[part 4 of 6: packages /MICROSAR/KeyM_swc/Interfaces to /MICROSAR/KeyM_swc/ComponentTypes]
AUTOSAR XML (schema 00049)
package /MICROSAR/KeyM_swc/Interfaces  (continued)
  153 x client server interface, all with is-service=true, service-kind=VENDOR-SPECIFIC:  (continued)
    KeyMCertificateElement_Ssa_TrustModelEcuCsr_SigAlgoId_008  # Service of the certificate sub module to access certificate elements.
      operation CertificateElementGet: possible-error=[KeyMCertificateElement_Ssa_TrustModelEcuCsr_SigAlgoId_008/E_NOT_OK, KeyMCertificateElement_Ssa_TrustModelEcuCsr_SigAlgoId_008/KEYM_E_KEY_CERT_SIZE_MISMATCH, KeyMCertificateElement_Ssa_TrustModelEcuCsr_SigAlgoId_008/KEYM_E_PARAMETER_MISMATCH, KeyMCertificateElement_Ssa_TrustModelEcuCsr_SigAlgoId_008/KEYM_E_KEY_CERT_INVALID, KeyMCertificateElement_Ssa_TrustModelEcuCsr_SigAlgoId_008/KEYM_E_KEY_CERT_EMPTY]  # Provides the content of a specific certificate element. The certificate configuration defines how the certificate submodule can find the element, e.g. by providing the object identifier (OID). This function is used to retrieve this information if only one element is assigned to the respective OID.
        arg CertificateElementData: type=KeyM_CertificateElementType_Ssa_TrustModelEcuCsr_SigAlgoId_008, direction=OUT, server-argument-impl-policy=USE-ARRAY-BASE-TYPE  # Holds a pointer to the memory location which will hold the certificate element.
        arg CertificateDataLength: type=uint32, direction=OUT  # Contains the length in bytes of certificate element.
      operation CertificateElementGetByIndex: possible-error=[KeyMCertificateElement_Ssa_TrustModelEcuCsr_SigAlgoId_008/E_NOT_OK, KeyMCertificateElement_Ssa_TrustModelEcuCsr_SigAlgoId_008/KEYM_E_KEY_CERT_SIZE_MISMATCH, KeyMCertificateElement_Ssa_TrustModelEcuCsr_SigAlgoId_008/KEYM_E_PARAMETER_MISMATCH, KeyMCertificateElement_Ssa_TrustModelEcuCsr_SigAlgoId_008/KEYM_E_KEY_CERT_INVALID, KeyMCertificateElement_Ssa_TrustModelEcuCsr_SigAlgoId_008/KEYM_E_KEY_CERT_EMPTY]  # This operation provides data from a specific certificate element.
        arg Index: type=uint16, direction=IN  # This is the index to dedicated element in the list
        arg CertificateElementData: type=KeyM_CertificateElementType_Ssa_TrustModelEcuCsr_SigAlgoId_008, direction=OUT, server-argument-impl-policy=USE-ARRAY-BASE-TYPE  # Holds a pointer to the memory location which will hold the certificate element.
        arg CertificateDataLength: type=uint32, direction=OUT  # Contains the length in bytes of certificate element.
      operation CertificateElementGetCount: possible-error=[KeyMCertificateElement_Ssa_TrustModelEcuCsr_SigAlgoId_008/E_NOT_OK, KeyMCertificateElement_Ssa_TrustModelEcuCsr_SigAlgoId_008/KEYM_E_KEY_CERT_SIZE_MISMATCH, KeyMCertificateElement_Ssa_TrustModelEcuCsr_SigAlgoId_008/KEYM_E_PARAMETER_MISMATCH, KeyMCertificateElement_Ssa_TrustModelEcuCsr_SigAlgoId_008/KEYM_E_KEY_CERT_INVALID, KeyMCertificateElement_Ssa_TrustModelEcuCsr_SigAlgoId_008/KEYM_E_KEY_CERT_EMPTY]  # This operation returns the amount of items available for a certificate element.
        arg count: type=uint16, direction=OUT  # Number of items available for an element.
      5 x error:
        E_NOT_OK: error-code=1  # The service request failed.
        KEYM_E_KEY_CERT_SIZE_MISMATCH: error-code=4  # The service request failed. Parameter size does not match the expected value.
        KEYM_E_PARAMETER_MISMATCH: error-code=5  # The service request failed. Parameter to function does not provide the expected value.
        KEYM_E_KEY_CERT_EMPTY: error-code=10  # The service request failed. The requested key or certificate is not available, slot is empty.
        KEYM_E_KEY_CERT_INVALID: error-code=6  # The service request failed. Key or certificate is invalid and cannot be used for the operation.
    KeyMCertificateElement_Ssa_TrustModelEcuCsr_validityNotBefore_008  # Service of the certificate sub module to access certificate elements.
      operation CertificateElementGet: possible-error=[KeyMCertificateElement_Ssa_TrustModelEcuCsr_validityNotBefore_008/E_NOT_OK, KeyMCertificateElement_Ssa_TrustModelEcuCsr_validityNotBefore_008/KEYM_E_KEY_CERT_SIZE_MISMATCH, KeyMCertificateElement_Ssa_TrustModelEcuCsr_validityNotBefore_008/KEYM_E_PARAMETER_MISMATCH, KeyMCertificateElement_Ssa_TrustModelEcuCsr_validityNotBefore_008/KEYM_E_KEY_CERT_INVALID, KeyMCertificateElement_Ssa_TrustModelEcuCsr_validityNotBefore_008/KEYM_E_KEY_CERT_EMPTY]  # Provides the content of a specific certificate element. The certificate configuration defines how the certificate submodule can find the element, e.g. by providing the object identifier (OID). This function is used to retrieve this information if only one element is assigned to the respective OID.
        arg CertificateElementData: type=KeyM_CertificateElementType_Ssa_TrustModelEcuCsr_validityNotBefore_008, direction=OUT, server-argument-impl-policy=USE-ARRAY-BASE-TYPE  # Holds a pointer to the memory location which will hold the certificate element.
        arg CertificateDataLength: type=uint32, direction=OUT  # Contains the length in bytes of certificate element.
      operation CertificateElementGetByIndex: possible-error=[KeyMCertificateElement_Ssa_TrustModelEcuCsr_validityNotBefore_008/E_NOT_OK, KeyMCertificateElement_Ssa_TrustModelEcuCsr_validityNotBefore_008/KEYM_E_KEY_CERT_SIZE_MISMATCH, KeyMCertificateElement_Ssa_TrustModelEcuCsr_validityNotBefore_008/KEYM_E_PARAMETER_MISMATCH, KeyMCertificateElement_Ssa_TrustModelEcuCsr_validityNotBefore_008/KEYM_E_KEY_CERT_INVALID, KeyMCertificateElement_Ssa_TrustModelEcuCsr_validityNotBefore_008/KEYM_E_KEY_CERT_EMPTY]  # This operation provides data from a specific certificate element.
        arg Index: type=uint16, direction=IN  # This is the index to dedicated element in the list
        arg CertificateElementData: type=KeyM_CertificateElementType_Ssa_TrustModelEcuCsr_validityNotBefore_008, direction=OUT, server-argument-impl-policy=USE-ARRAY-BASE-TYPE  # Holds a pointer to the memory location which will hold the certificate element.
        arg CertificateDataLength: type=uint32, direction=OUT  # Contains the length in bytes of certificate element.
      operation CertificateElementGetCount: possible-error=[KeyMCertificateElement_Ssa_TrustModelEcuCsr_validityNotBefore_008/E_NOT_OK, KeyMCertificateElement_Ssa_TrustModelEcuCsr_validityNotBefore_008/KEYM_E_KEY_CERT_SIZE_MISMATCH, KeyMCertificateElement_Ssa_TrustModelEcuCsr_validityNotBefore_008/KEYM_E_PARAMETER_MISMATCH, KeyMCertificateElement_Ssa_TrustModelEcuCsr_validityNotBefore_008/KEYM_E_KEY_CERT_INVALID, KeyMCertificateElement_Ssa_TrustModelEcuCsr_validityNotBefore_008/KEYM_E_KEY_CERT_EMPTY]  # This operation returns the amount of items available for a certificate element.
        arg count: type=uint16, direction=OUT  # Number of items available for an element.
      5 x error:
        E_NOT_OK: error-code=1  # The service request failed.
        KEYM_E_KEY_CERT_SIZE_MISMATCH: error-code=4  # The service request failed. Parameter size does not match the expected value.
        KEYM_E_PARAMETER_MISMATCH: error-code=5  # The service request failed. Parameter to function does not provide the expected value.
        KEYM_E_KEY_CERT_EMPTY: error-code=10  # The service request failed. The requested key or certificate is not available, slot is empty.
        KEYM_E_KEY_CERT_INVALID: error-code=6  # The service request failed. Key or certificate is invalid and cannot be used for the operation.
    KeyMCertificateElement_Ssa_TrustModelEcuCsr_validityNotAfter_008  # Service of the certificate sub module to access certificate elements.
      operation CertificateElementGet: possible-error=[KeyMCertificateElement_Ssa_TrustModelEcuCsr_validityNotAfter_008/E_NOT_OK, KeyMCertificateElement_Ssa_TrustModelEcuCsr_validityNotAfter_008/KEYM_E_KEY_CERT_SIZE_MISMATCH, KeyMCertificateElement_Ssa_TrustModelEcuCsr_validityNotAfter_008/KEYM_E_PARAMETER_MISMATCH, KeyMCertificateElement_Ssa_TrustModelEcuCsr_validityNotAfter_008/KEYM_E_KEY_CERT_INVALID, KeyMCertificateElement_Ssa_TrustModelEcuCsr_validityNotAfter_008/KEYM_E_KEY_CERT_EMPTY]  # Provides the content of a specific certificate element. The certificate configuration defines how the certificate submodule can find the element, e.g. by providing the object identifier (OID). This function is used to retrieve this information if only one element is assigned to the respective OID.
        arg CertificateElementData: type=KeyM_CertificateElementType_Ssa_TrustModelEcuCsr_validityNotAfter_008, direction=OUT, server-argument-impl-policy=USE-ARRAY-BASE-TYPE  # Holds a pointer to the memory location which will hold the certificate element.
        arg CertificateDataLength: type=uint32, direction=OUT  # Contains the length in bytes of certificate element.
      operation CertificateElementGetByIndex: possible-error=[KeyMCertificateElement_Ssa_TrustModelEcuCsr_validityNotAfter_008/E_NOT_OK, KeyMCertificateElement_Ssa_TrustModelEcuCsr_validityNotAfter_008/KEYM_E_KEY_CERT_SIZE_MISMATCH, KeyMCertificateElement_Ssa_TrustModelEcuCsr_validityNotAfter_008/KEYM_E_PARAMETER_MISMATCH, KeyMCertificateElement_Ssa_TrustModelEcuCsr_validityNotAfter_008/KEYM_E_KEY_CERT_INVALID, KeyMCertificateElement_Ssa_TrustModelEcuCsr_validityNotAfter_008/KEYM_E_KEY_CERT_EMPTY]  # This operation provides data from a specific certificate element.
        arg Index: type=uint16, direction=IN  # This is the index to dedicated element in the list
        arg CertificateElementData: type=KeyM_CertificateElementType_Ssa_TrustModelEcuCsr_validityNotAfter_008, direction=OUT, server-argument-impl-policy=USE-ARRAY-BASE-TYPE  # Holds a pointer to the memory location which will hold the certificate element.
        arg CertificateDataLength: type=uint32, direction=OUT  # Contains the length in bytes of certificate element.
      operation CertificateElementGetCount: possible-error=[KeyMCertificateElement_Ssa_TrustModelEcuCsr_validityNotAfter_008/E_NOT_OK, KeyMCertificateElement_Ssa_TrustModelEcuCsr_validityNotAfter_008/KEYM_E_KEY_CERT_SIZE_MISMATCH, KeyMCertificateElement_Ssa_TrustModelEcuCsr_validityNotAfter_008/KEYM_E_PARAMETER_MISMATCH, KeyMCertificateElement_Ssa_TrustModelEcuCsr_validityNotAfter_008/KEYM_E_KEY_CERT_INVALID, KeyMCertificateElement_Ssa_TrustModelEcuCsr_validityNotAfter_008/KEYM_E_KEY_CERT_EMPTY]  # This operation returns the amount of items available for a certificate element.
        arg count: type=uint16, direction=OUT  # Number of items available for an element.
      5 x error:
        E_NOT_OK: error-code=1  # The service request failed.
        KEYM_E_KEY_CERT_SIZE_MISMATCH: error-code=4  # The service request failed. Parameter size does not match the expected value.
        KEYM_E_PARAMETER_MISMATCH: error-code=5  # The service request failed. Parameter to function does not provide the expected value.
        KEYM_E_KEY_CERT_EMPTY: error-code=10  # The service request failed. The requested key or certificate is not available, slot is empty.
        KEYM_E_KEY_CERT_INVALID: error-code=6  # The service request failed. Key or certificate is invalid and cannot be used for the operation.
    KeyMCertificateElement_Ssa_TrustModelEcuCsr_subject_008  # Service of the certificate sub module to access certificate elements.
      operation CertificateElementGet: possible-error=[KeyMCertificateElement_Ssa_TrustModelEcuCsr_subject_008/E_NOT_OK, KeyMCertificateElement_Ssa_TrustModelEcuCsr_subject_008/KEYM_E_KEY_CERT_SIZE_MISMATCH, KeyMCertificateElement_Ssa_TrustModelEcuCsr_subject_008/KEYM_E_PARAMETER_MISMATCH, KeyMCertificateElement_Ssa_TrustModelEcuCsr_subject_008/KEYM_E_KEY_CERT_INVALID, KeyMCertificateElement_Ssa_TrustModelEcuCsr_subject_008/KEYM_E_KEY_CERT_EMPTY]  # Provides the content of a specific certificate element. The certificate configuration defines how the certificate submodule can find the element, e.g. by providing the object identifier (OID). This function is used to retrieve this information if only one element is assigned to the respective OID.
        arg CertificateElementData: type=KeyM_CertificateElementType_Ssa_TrustModelEcuCsr_subject_008, direction=OUT, server-argument-impl-policy=USE-ARRAY-BASE-TYPE  # Holds a pointer to the memory location which will hold the certificate element.
        arg CertificateDataLength: type=uint32, direction=OUT  # Contains the length in bytes of certificate element.
      operation CertificateElementGetByIndex: possible-error=[KeyMCertificateElement_Ssa_TrustModelEcuCsr_subject_008/E_NOT_OK, KeyMCertificateElement_Ssa_TrustModelEcuCsr_subject_008/KEYM_E_KEY_CERT_SIZE_MISMATCH, KeyMCertificateElement_Ssa_TrustModelEcuCsr_subject_008/KEYM_E_PARAMETER_MISMATCH, KeyMCertificateElement_Ssa_TrustModelEcuCsr_subject_008/KEYM_E_KEY_CERT_INVALID, KeyMCertificateElement_Ssa_TrustModelEcuCsr_subject_008/KEYM_E_KEY_CERT_EMPTY]  # This operation provides data from a specific certificate element.
        arg Index: type=uint16, direction=IN  # This is the index to dedicated element in the list
        arg CertificateElementData: type=KeyM_CertificateElementType_Ssa_TrustModelEcuCsr_subject_008, direction=OUT, server-argument-impl-policy=USE-ARRAY-BASE-TYPE  # Holds a pointer to the memory location which will hold the certificate element.
        arg CertificateDataLength: type=uint32, direction=OUT  # Contains the length in bytes of certificate element.
      operation CertificateElementGetCount: possible-error=[KeyMCertificateElement_Ssa_TrustModelEcuCsr_subject_008/E_NOT_OK, KeyMCertificateElement_Ssa_TrustModelEcuCsr_subject_008/KEYM_E_KEY_CERT_SIZE_MISMATCH, KeyMCertificateElement_Ssa_TrustModelEcuCsr_subject_008/KEYM_E_PARAMETER_MISMATCH, KeyMCertificateElement_Ssa_TrustModelEcuCsr_subject_008/KEYM_E_KEY_CERT_INVALID, KeyMCertificateElement_Ssa_TrustModelEcuCsr_subject_008/KEYM_E_KEY_CERT_EMPTY]  # This operation returns the amount of items available for a certificate element.
        arg count: type=uint16, direction=OUT  # Number of items available for an element.
      5 x error:
        E_NOT_OK: error-code=1  # The service request failed.
        KEYM_E_KEY_CERT_SIZE_MISMATCH: error-code=4  # The service request failed. Parameter size does not match the expected value.
        KEYM_E_PARAMETER_MISMATCH: error-code=5  # The service request failed. Parameter to function does not provide the expected value.
        KEYM_E_KEY_CERT_EMPTY: error-code=10  # The service request failed. The requested key or certificate is not available, slot is empty.
        KEYM_E_KEY_CERT_INVALID: error-code=6  # The service request failed. Key or certificate is invalid and cannot be used for the operation.
    KeyMCertificateElement_Ssa_TrustModelEcuCsr_SubjectPublicKeyInfoAlgo_008  # Service of the certificate sub module to access certificate elements.
      operation CertificateElementGet: possible-error=[KeyMCertificateElement_Ssa_TrustModelEcuCsr_SubjectPublicKeyInfoAlgo_008/E_NOT_OK, KeyMCertificateElement_Ssa_TrustModelEcuCsr_SubjectPublicKeyInfoAlgo_008/KEYM_E_KEY_CERT_SIZE_MISMATCH, KeyMCertificateElement_Ssa_TrustModelEcuCsr_SubjectPublicKeyInfoAlgo_008/KEYM_E_PARAMETER_MISMATCH, KeyMCertificateElement_Ssa_TrustModelEcuCsr_SubjectPublicKeyInfoAlgo_008/KEYM_E_KEY_CERT_INVALID, KeyMCertificateElement_Ssa_TrustModelEcuCsr_SubjectPublicKeyInfoAlgo_008/KEYM_E_KEY_CERT_EMPTY]  # Provides the content of a specific certificate element. The certificate configuration defines how the certificate submodule can find the element, e.g. by providing the object identifier (OID). This function is used to retrieve this information if only one element is assigned to the respective OID.
        arg CertificateElementData: type=KeyM_CertificateElementType_Ssa_TrustModelEcuCsr_SubjectPublicKeyInfoAlgo_008, direction=OUT, server-argument-impl-policy=USE-ARRAY-BASE-TYPE  # Holds a pointer to the memory location which will hold the certificate element.
        arg CertificateDataLength: type=uint32, direction=OUT  # Contains the length in bytes of certificate element.
      operation CertificateElementGetByIndex: possible-error=[KeyMCertificateElement_Ssa_TrustModelEcuCsr_SubjectPublicKeyInfoAlgo_008/E_NOT_OK, KeyMCertificateElement_Ssa_TrustModelEcuCsr_SubjectPublicKeyInfoAlgo_008/KEYM_E_KEY_CERT_SIZE_MISMATCH, KeyMCertificateElement_Ssa_TrustModelEcuCsr_SubjectPublicKeyInfoAlgo_008/KEYM_E_PARAMETER_MISMATCH, KeyMCertificateElement_Ssa_TrustModelEcuCsr_SubjectPublicKeyInfoAlgo_008/KEYM_E_KEY_CERT_INVALID, KeyMCertificateElement_Ssa_TrustModelEcuCsr_SubjectPublicKeyInfoAlgo_008/KEYM_E_KEY_CERT_EMPTY]  # This operation provides data from a specific certificate element.
        arg Index: type=uint16, direction=IN  # This is the index to dedicated element in the list
        arg CertificateElementData: type=KeyM_CertificateElementType_Ssa_TrustModelEcuCsr_SubjectPublicKeyInfoAlgo_008, direction=OUT, server-argument-impl-policy=USE-ARRAY-BASE-TYPE  # Holds a pointer to the memory location which will hold the certificate element.
        arg CertificateDataLength: type=uint32, direction=OUT  # Contains the length in bytes of certificate element.
      operation CertificateElementGetCount: possible-error=[KeyMCertificateElement_Ssa_TrustModelEcuCsr_SubjectPublicKeyInfoAlgo_008/E_NOT_OK, KeyMCertificateElement_Ssa_TrustModelEcuCsr_SubjectPublicKeyInfoAlgo_008/KEYM_E_KEY_CERT_SIZE_MISMATCH, KeyMCertificateElement_Ssa_TrustModelEcuCsr_SubjectPublicKeyInfoAlgo_008/KEYM_E_PARAMETER_MISMATCH, KeyMCertificateElement_Ssa_TrustModelEcuCsr_SubjectPublicKeyInfoAlgo_008/KEYM_E_KEY_CERT_INVALID, KeyMCertificateElement_Ssa_TrustModelEcuCsr_SubjectPublicKeyInfoAlgo_008/KEYM_E_KEY_CERT_EMPTY]  # This operation returns the amount of items available for a certificate element.
        arg count: type=uint16, direction=OUT  # Number of items available for an element.
      5 x error:
        E_NOT_OK: error-code=1  # The service request failed.
        KEYM_E_KEY_CERT_SIZE_MISMATCH: error-code=4  # The service request failed. Parameter size does not match the expected value.
        KEYM_E_PARAMETER_MISMATCH: error-code=5  # The service request failed. Parameter to function does not provide the expected value.
        KEYM_E_KEY_CERT_EMPTY: error-code=10  # The service request failed. The requested key or certificate is not available, slot is empty.
        KEYM_E_KEY_CERT_INVALID: error-code=6  # The service request failed. Key or certificate is invalid and cannot be used for the operation.
    KeyMCertificateElement_Ssa_TrustModelEcuCsr_SubjectPublicKeyInfoKey_008  # Service of the certificate sub module to access certificate elements.
      operation CertificateElementGet: possible-error=[KeyMCertificateElement_Ssa_TrustModelEcuCsr_SubjectPublicKeyInfoKey_008/E_NOT_OK, KeyMCertificateElement_Ssa_TrustModelEcuCsr_SubjectPublicKeyInfoKey_008/KEYM_E_KEY_CERT_SIZE_MISMATCH, KeyMCertificateElement_Ssa_TrustModelEcuCsr_SubjectPublicKeyInfoKey_008/KEYM_E_PARAMETER_MISMATCH, KeyMCertificateElement_Ssa_TrustModelEcuCsr_SubjectPublicKeyInfoKey_008/KEYM_E_KEY_CERT_INVALID, KeyMCertificateElement_Ssa_TrustModelEcuCsr_SubjectPublicKeyInfoKey_008/KEYM_E_KEY_CERT_EMPTY]  # Provides the content of a specific certificate element. The certificate configuration defines how the certificate submodule can find the element, e.g. by providing the object identifier (OID). This function is used to retrieve this information if only one element is assigned to the respective OID.
        arg CertificateElementData: type=KeyM_CertificateElementType_Ssa_TrustModelEcuCsr_SubjectPublicKeyInfoKey_008, direction=OUT, server-argument-impl-policy=USE-ARRAY-BASE-TYPE  # Holds a pointer to the memory location which will hold the certificate element.
        arg CertificateDataLength: type=uint32, direction=OUT  # Contains the length in bytes of certificate element.
      operation CertificateElementGetByIndex: possible-error=[KeyMCertificateElement_Ssa_TrustModelEcuCsr_SubjectPublicKeyInfoKey_008/E_NOT_OK, KeyMCertificateElement_Ssa_TrustModelEcuCsr_SubjectPublicKeyInfoKey_008/KEYM_E_KEY_CERT_SIZE_MISMATCH, KeyMCertificateElement_Ssa_TrustModelEcuCsr_SubjectPublicKeyInfoKey_008/KEYM_E_PARAMETER_MISMATCH, KeyMCertificateElement_Ssa_TrustModelEcuCsr_SubjectPublicKeyInfoKey_008/KEYM_E_KEY_CERT_INVALID, KeyMCertificateElement_Ssa_TrustModelEcuCsr_SubjectPublicKeyInfoKey_008/KEYM_E_KEY_CERT_EMPTY]  # This operation provides data from a specific certificate element.
        arg Index: type=uint16, direction=IN  # This is the index to dedicated element in the list
        arg CertificateElementData: type=KeyM_CertificateElementType_Ssa_TrustModelEcuCsr_SubjectPublicKeyInfoKey_008, direction=OUT, server-argument-impl-policy=USE-ARRAY-BASE-TYPE  # Holds a pointer to the memory location which will hold the certificate element.
        arg CertificateDataLength: type=uint32, direction=OUT  # Contains the length in bytes of certificate element.
      operation CertificateElementGetCount: possible-error=[KeyMCertificateElement_Ssa_TrustModelEcuCsr_SubjectPublicKeyInfoKey_008/E_NOT_OK, KeyMCertificateElement_Ssa_TrustModelEcuCsr_SubjectPublicKeyInfoKey_008/KEYM_E_KEY_CERT_SIZE_MISMATCH, KeyMCertificateElement_Ssa_TrustModelEcuCsr_SubjectPublicKeyInfoKey_008/KEYM_E_PARAMETER_MISMATCH, KeyMCertificateElement_Ssa_TrustModelEcuCsr_SubjectPublicKeyInfoKey_008/KEYM_E_KEY_CERT_INVALID, KeyMCertificateElement_Ssa_TrustModelEcuCsr_SubjectPublicKeyInfoKey_008/KEYM_E_KEY_CERT_EMPTY]  # This operation returns the amount of items available for a certificate element.
        arg count: type=uint16, direction=OUT  # Number of items available for an element.
      5 x error:
        E_NOT_OK: error-code=1  # The service request failed.
        KEYM_E_KEY_CERT_SIZE_MISMATCH: error-code=4  # The service request failed. Parameter size does not match the expected value.
        KEYM_E_PARAMETER_MISMATCH: error-code=5  # The service request failed. Parameter to function does not provide the expected value.
        KEYM_E_KEY_CERT_EMPTY: error-code=10  # The service request failed. The requested key or certificate is not available, slot is empty.
        KEYM_E_KEY_CERT_INVALID: error-code=6  # The service request failed. Key or certificate is invalid and cannot be used for the operation.
    KeyMCertificateElement_Ssa_TrustModelEcuCsr_Issuer_008  # Service of the certificate sub module to access certificate elements.
      operation CertificateElementGet: possible-error=[KeyMCertificateElement_Ssa_TrustModelEcuCsr_Issuer_008/E_NOT_OK, KeyMCertificateElement_Ssa_TrustModelEcuCsr_Issuer_008/KEYM_E_KEY_CERT_SIZE_MISMATCH, KeyMCertificateElement_Ssa_TrustModelEcuCsr_Issuer_008/KEYM_E_PARAMETER_MISMATCH, KeyMCertificateElement_Ssa_TrustModelEcuCsr_Issuer_008/KEYM_E_KEY_CERT_INVALID, KeyMCertificateElement_Ssa_TrustModelEcuCsr_Issuer_008/KEYM_E_KEY_CERT_EMPTY]  # Provides the content of a specific certificate element. The certificate configuration defines how the certificate submodule can find the element, e.g. by providing the object identifier (OID). This function is used to retrieve this information if only one element is assigned to the respective OID.
        arg CertificateElementData: type=KeyM_CertificateElementType_Ssa_TrustModelEcuCsr_Issuer_008, direction=OUT, server-argument-impl-policy=USE-ARRAY-BASE-TYPE  # Holds a pointer to the memory location which will hold the certificate element.
        arg CertificateDataLength: type=uint32, direction=OUT  # Contains the length in bytes of certificate element.
      operation CertificateElementGetByIndex: possible-error=[KeyMCertificateElement_Ssa_TrustModelEcuCsr_Issuer_008/E_NOT_OK, KeyMCertificateElement_Ssa_TrustModelEcuCsr_Issuer_008/KEYM_E_KEY_CERT_SIZE_MISMATCH, KeyMCertificateElement_Ssa_TrustModelEcuCsr_Issuer_008/KEYM_E_PARAMETER_MISMATCH, KeyMCertificateElement_Ssa_TrustModelEcuCsr_Issuer_008/KEYM_E_KEY_CERT_INVALID, KeyMCertificateElement_Ssa_TrustModelEcuCsr_Issuer_008/KEYM_E_KEY_CERT_EMPTY]  # This operation provides data from a specific certificate element.
        arg Index: type=uint16, direction=IN  # This is the index to dedicated element in the list
        arg CertificateElementData: type=KeyM_CertificateElementType_Ssa_TrustModelEcuCsr_Issuer_008, direction=OUT, server-argument-impl-policy=USE-ARRAY-BASE-TYPE  # Holds a pointer to the memory location which will hold the certificate element.
        arg CertificateDataLength: type=uint32, direction=OUT  # Contains the length in bytes of certificate element.
      operation CertificateElementGetCount: possible-error=[KeyMCertificateElement_Ssa_TrustModelEcuCsr_Issuer_008/E_NOT_OK, KeyMCertificateElement_Ssa_TrustModelEcuCsr_Issuer_008/KEYM_E_KEY_CERT_SIZE_MISMATCH, KeyMCertificateElement_Ssa_TrustModelEcuCsr_Issuer_008/KEYM_E_PARAMETER_MISMATCH, KeyMCertificateElement_Ssa_TrustModelEcuCsr_Issuer_008/KEYM_E_KEY_CERT_INVALID, KeyMCertificateElement_Ssa_TrustModelEcuCsr_Issuer_008/KEYM_E_KEY_CERT_EMPTY]  # This operation returns the amount of items available for a certificate element.
        arg count: type=uint16, direction=OUT  # Number of items available for an element.
      5 x error:
        E_NOT_OK: error-code=1  # The service request failed.
        KEYM_E_KEY_CERT_SIZE_MISMATCH: error-code=4  # The service request failed. Parameter size does not match the expected value.
        KEYM_E_PARAMETER_MISMATCH: error-code=5  # The service request failed. Parameter to function does not provide the expected value.
        KEYM_E_KEY_CERT_EMPTY: error-code=10  # The service request failed. The requested key or certificate is not available, slot is empty.
        KEYM_E_KEY_CERT_INVALID: error-code=6  # The service request failed. Key or certificate is invalid and cannot be used for the operation.
    KeyMCertificateElement_Ssa_TrustModelEcuCsr_signatureAlgorithm_008  # Service of the certificate sub module to access certificate elements.
      operation CertificateElementGet: possible-error=[KeyMCertificateElement_Ssa_TrustModelEcuCsr_signatureAlgorithm_008/E_NOT_OK, KeyMCertificateElement_Ssa_TrustModelEcuCsr_signatureAlgorithm_008/KEYM_E_KEY_CERT_SIZE_MISMATCH, KeyMCertificateElement_Ssa_TrustModelEcuCsr_signatureAlgorithm_008/KEYM_E_PARAMETER_MISMATCH, KeyMCertificateElement_Ssa_TrustModelEcuCsr_signatureAlgorithm_008/KEYM_E_KEY_CERT_INVALID, KeyMCertificateElement_Ssa_TrustModelEcuCsr_signatureAlgorithm_008/KEYM_E_KEY_CERT_EMPTY]  # Provides the content of a specific certificate element. The certificate configuration defines how the certificate submodule can find the element, e.g. by providing the object identifier (OID). This function is used to retrieve this information if only one element is assigned to the respective OID.
        arg CertificateElementData: type=KeyM_CertificateElementType_Ssa_TrustModelEcuCsr_signatureAlgorithm_008, direction=OUT, server-argument-impl-policy=USE-ARRAY-BASE-TYPE  # Holds a pointer to the memory location which will hold the certificate element.
        arg CertificateDataLength: type=uint32, direction=OUT  # Contains the length in bytes of certificate element.
      operation CertificateElementGetByIndex: possible-error=[KeyMCertificateElement_Ssa_TrustModelEcuCsr_signatureAlgorithm_008/E_NOT_OK, KeyMCertificateElement_Ssa_TrustModelEcuCsr_signatureAlgorithm_008/KEYM_E_KEY_CERT_SIZE_MISMATCH, KeyMCertificateElement_Ssa_TrustModelEcuCsr_signatureAlgorithm_008/KEYM_E_PARAMETER_MISMATCH, KeyMCertificateElement_Ssa_TrustModelEcuCsr_signatureAlgorithm_008/KEYM_E_KEY_CERT_INVALID, KeyMCertificateElement_Ssa_TrustModelEcuCsr_signatureAlgorithm_008/KEYM_E_KEY_CERT_EMPTY]  # This operation provides data from a specific certificate element.
        arg Index: type=uint16, direction=IN  # This is the index to dedicated element in the list
        arg CertificateElementData: type=KeyM_CertificateElementType_Ssa_TrustModelEcuCsr_signatureAlgorithm_008, direction=OUT, server-argument-impl-policy=USE-ARRAY-BASE-TYPE  # Holds a pointer to the memory location which will hold the certificate element.
        arg CertificateDataLength: type=uint32, direction=OUT  # Contains the length in bytes of certificate element.
      operation CertificateElementGetCount: possible-error=[KeyMCertificateElement_Ssa_TrustModelEcuCsr_signatureAlgorithm_008/E_NOT_OK, KeyMCertificateElement_Ssa_TrustModelEcuCsr_signatureAlgorithm_008/KEYM_E_KEY_CERT_SIZE_MISMATCH, KeyMCertificateElement_Ssa_TrustModelEcuCsr_signatureAlgorithm_008/KEYM_E_PARAMETER_MISMATCH, KeyMCertificateElement_Ssa_TrustModelEcuCsr_signatureAlgorithm_008/KEYM_E_KEY_CERT_INVALID, KeyMCertificateElement_Ssa_TrustModelEcuCsr_signatureAlgorithm_008/KEYM_E_KEY_CERT_EMPTY]  # This operation returns the amount of items available for a certificate element.
        arg count: type=uint16, direction=OUT  # Number of items available for an element.
      5 x error:
        E_NOT_OK: error-code=1  # The service request failed.
        KEYM_E_KEY_CERT_SIZE_MISMATCH: error-code=4  # The service request failed. Parameter size does not match the expected value.
        KEYM_E_PARAMETER_MISMATCH: error-code=5  # The service request failed. Parameter to function does not provide the expected value.
        KEYM_E_KEY_CERT_EMPTY: error-code=10  # The service request failed. The requested key or certificate is not available, slot is empty.
        KEYM_E_KEY_CERT_INVALID: error-code=6  # The service request failed. Key or certificate is invalid and cannot be used for the operation.
    KeyMCertificateElement_Ssa_TrustModelEcuCsr_signatureValue_008  # Service of the certificate sub module to access certificate elements.
      operation CertificateElementGet: possible-error=[KeyMCertificateElement_Ssa_TrustModelEcuCsr_signatureValue_008/E_NOT_OK, KeyMCertificateElement_Ssa_TrustModelEcuCsr_signatureValue_008/KEYM_E_KEY_CERT_SIZE_MISMATCH, KeyMCertificateElement_Ssa_TrustModelEcuCsr_signatureValue_008/KEYM_E_PARAMETER_MISMATCH, KeyMCertificateElement_Ssa_TrustModelEcuCsr_signatureValue_008/KEYM_E_KEY_CERT_INVALID, KeyMCertificateElement_Ssa_TrustModelEcuCsr_signatureValue_008/KEYM_E_KEY_CERT_EMPTY]  # Provides the content of a specific certificate element. The certificate configuration defines how the certificate submodule can find the element, e.g. by providing the object identifier (OID). This function is used to retrieve this information if only one element is assigned to the respective OID.
        arg CertificateElementData: type=KeyM_CertificateElementType_Ssa_TrustModelEcuCsr_signatureValue_008, direction=OUT, server-argument-impl-policy=USE-ARRAY-BASE-TYPE  # Holds a pointer to the memory location which will hold the certificate element.
        arg CertificateDataLength: type=uint32, direction=OUT  # Contains the length in bytes of certificate element.
      operation CertificateElementGetByIndex: possible-error=[KeyMCertificateElement_Ssa_TrustModelEcuCsr_signatureValue_008/E_NOT_OK, KeyMCertificateElement_Ssa_TrustModelEcuCsr_signatureValue_008/KEYM_E_KEY_CERT_SIZE_MISMATCH, KeyMCertificateElement_Ssa_TrustModelEcuCsr_signatureValue_008/KEYM_E_PARAMETER_MISMATCH, KeyMCertificateElement_Ssa_TrustModelEcuCsr_signatureValue_008/KEYM_E_KEY_CERT_INVALID, KeyMCertificateElement_Ssa_TrustModelEcuCsr_signatureValue_008/KEYM_E_KEY_CERT_EMPTY]  # This operation provides data from a specific certificate element.
        arg Index: type=uint16, direction=IN  # This is the index to dedicated element in the list
        arg CertificateElementData: type=KeyM_CertificateElementType_Ssa_TrustModelEcuCsr_signatureValue_008, direction=OUT, server-argument-impl-policy=USE-ARRAY-BASE-TYPE  # Holds a pointer to the memory location which will hold the certificate element.
        arg CertificateDataLength: type=uint32, direction=OUT  # Contains the length in bytes of certificate element.
      operation CertificateElementGetCount: possible-error=[KeyMCertificateElement_Ssa_TrustModelEcuCsr_signatureValue_008/E_NOT_OK, KeyMCertificateElement_Ssa_TrustModelEcuCsr_signatureValue_008/KEYM_E_KEY_CERT_SIZE_MISMATCH, KeyMCertificateElement_Ssa_TrustModelEcuCsr_signatureValue_008/KEYM_E_PARAMETER_MISMATCH, KeyMCertificateElement_Ssa_TrustModelEcuCsr_signatureValue_008/KEYM_E_KEY_CERT_INVALID, KeyMCertificateElement_Ssa_TrustModelEcuCsr_signatureValue_008/KEYM_E_KEY_CERT_EMPTY]  # This operation returns the amount of items available for a certificate element.
        arg count: type=uint16, direction=OUT  # Number of items available for an element.
      5 x error:
        E_NOT_OK: error-code=1  # The service request failed.
        KEYM_E_KEY_CERT_SIZE_MISMATCH: error-code=4  # The service request failed. Parameter size does not match the expected value.
        KEYM_E_PARAMETER_MISMATCH: error-code=5  # The service request failed. Parameter to function does not provide the expected value.
        KEYM_E_KEY_CERT_EMPTY: error-code=10  # The service request failed. The requested key or certificate is not available, slot is empty.
        KEYM_E_KEY_CERT_INVALID: error-code=6  # The service request failed. Key or certificate is invalid and cannot be used for the operation.
    KeyMCertificateElement_Ssa_TrustModelEcuCsr_ext_uniqueECUID_007  # Service of the certificate sub module to access certificate elements.
      operation CertificateElementGet: possible-error=[KeyMCertificateElement_Ssa_TrustModelEcuCsr_ext_uniqueECUID_007/E_NOT_OK, KeyMCertificateElement_Ssa_TrustModelEcuCsr_ext_uniqueECUID_007/KEYM_E_KEY_CERT_SIZE_MISMATCH, KeyMCertificateElement_Ssa_TrustModelEcuCsr_ext_uniqueECUID_007/KEYM_E_PARAMETER_MISMATCH, KeyMCertificateElement_Ssa_TrustModelEcuCsr_ext_uniqueECUID_007/KEYM_E_KEY_CERT_INVALID, KeyMCertificateElement_Ssa_TrustModelEcuCsr_ext_uniqueECUID_007/KEYM_E_KEY_CERT_EMPTY]  # Provides the content of a specific certificate element. The certificate configuration defines how the certificate submodule can find the element, e.g. by providing the object identifier (OID). This function is used to retrieve this information if only one element is assigned to the respective OID.
        arg CertificateElementData: type=KeyM_CertificateElementType_Ssa_TrustModelEcuCsr_ext_uniqueECUID_007, direction=OUT, server-argument-impl-policy=USE-ARRAY-BASE-TYPE  # Holds a pointer to the memory location which will hold the certificate element.
        arg CertificateDataLength: type=uint32, direction=OUT  # Contains the length in bytes of certificate element.
      operation CertificateElementGetByIndex: possible-error=[KeyMCertificateElement_Ssa_TrustModelEcuCsr_ext_uniqueECUID_007/E_NOT_OK, KeyMCertificateElement_Ssa_TrustModelEcuCsr_ext_uniqueECUID_007/KEYM_E_KEY_CERT_SIZE_MISMATCH, KeyMCertificateElement_Ssa_TrustModelEcuCsr_ext_uniqueECUID_007/KEYM_E_PARAMETER_MISMATCH, KeyMCertificateElement_Ssa_TrustModelEcuCsr_ext_uniqueECUID_007/KEYM_E_KEY_CERT_INVALID, KeyMCertificateElement_Ssa_TrustModelEcuCsr_ext_uniqueECUID_007/KEYM_E_KEY_CERT_EMPTY]  # This operation provides data from a specific certificate element.
        arg Index: type=uint16, direction=IN  # This is the index to dedicated element in the list
        arg CertificateElementData: type=KeyM_CertificateElementType_Ssa_TrustModelEcuCsr_ext_uniqueECUID_007, direction=OUT, server-argument-impl-policy=USE-ARRAY-BASE-TYPE  # Holds a pointer to the memory location which will hold the certificate element.
        arg CertificateDataLength: type=uint32, direction=OUT  # Contains the length in bytes of certificate element.
      operation CertificateElementGetCount: possible-error=[KeyMCertificateElement_Ssa_TrustModelEcuCsr_ext_uniqueECUID_007/E_NOT_OK, KeyMCertificateElement_Ssa_TrustModelEcuCsr_ext_uniqueECUID_007/KEYM_E_KEY_CERT_SIZE_MISMATCH, KeyMCertificateElement_Ssa_TrustModelEcuCsr_ext_uniqueECUID_007/KEYM_E_PARAMETER_MISMATCH, KeyMCertificateElement_Ssa_TrustModelEcuCsr_ext_uniqueECUID_007/KEYM_E_KEY_CERT_INVALID, KeyMCertificateElement_Ssa_TrustModelEcuCsr_ext_uniqueECUID_007/KEYM_E_KEY_CERT_EMPTY]  # This operation returns the amount of items available for a certificate element.
        arg count: type=uint16, direction=OUT  # Number of items available for an element.
      5 x error:
        E_NOT_OK: error-code=1  # The service request failed.
        KEYM_E_KEY_CERT_SIZE_MISMATCH: error-code=4  # The service request failed. Parameter size does not match the expected value.
        KEYM_E_PARAMETER_MISMATCH: error-code=5  # The service request failed. Parameter to function does not provide the expected value.
        KEYM_E_KEY_CERT_EMPTY: error-code=10  # The service request failed. The requested key or certificate is not available, slot is empty.
        KEYM_E_KEY_CERT_INVALID: error-code=6  # The service request failed. Key or certificate is invalid and cannot be used for the operation.
    KeyMCertificateElement_Ssa_TrustModelEcuCsr_ext_specialEcu_007  # Service of the certificate sub module to access certificate elements.
      operation CertificateElementGet: possible-error=[KeyMCertificateElement_Ssa_TrustModelEcuCsr_ext_specialEcu_007/E_NOT_OK, KeyMCertificateElement_Ssa_TrustModelEcuCsr_ext_specialEcu_007/KEYM_E_KEY_CERT_SIZE_MISMATCH, KeyMCertificateElement_Ssa_TrustModelEcuCsr_ext_specialEcu_007/KEYM_E_PARAMETER_MISMATCH, KeyMCertificateElement_Ssa_TrustModelEcuCsr_ext_specialEcu_007/KEYM_E_KEY_CERT_INVALID, KeyMCertificateElement_Ssa_TrustModelEcuCsr_ext_specialEcu_007/KEYM_E_KEY_CERT_EMPTY]  # Provides the content of a specific certificate element. The certificate configuration defines how the certificate submodule can find the element, e.g. by providing the object identifier (OID). This function is used to retrieve this information if only one element is assigned to the respective OID.
        arg CertificateElementData: type=KeyM_CertificateElementType_Ssa_TrustModelEcuCsr_ext_specialEcu_007, direction=OUT, server-argument-impl-policy=USE-ARRAY-BASE-TYPE  # Holds a pointer to the memory location which will hold the certificate element.
        arg CertificateDataLength: type=uint32, direction=OUT  # Contains the length in bytes of certificate element.
      operation CertificateElementGetByIndex: possible-error=[KeyMCertificateElement_Ssa_TrustModelEcuCsr_ext_specialEcu_007/E_NOT_OK, KeyMCertificateElement_Ssa_TrustModelEcuCsr_ext_specialEcu_007/KEYM_E_KEY_CERT_SIZE_MISMATCH, KeyMCertificateElement_Ssa_TrustModelEcuCsr_ext_specialEcu_007/KEYM_E_PARAMETER_MISMATCH, KeyMCertificateElement_Ssa_TrustModelEcuCsr_ext_specialEcu_007/KEYM_E_KEY_CERT_INVALID, KeyMCertificateElement_Ssa_TrustModelEcuCsr_ext_specialEcu_007/KEYM_E_KEY_CERT_EMPTY]  # This operation provides data from a specific certificate element.
        arg Index: type=uint16, direction=IN  # This is the index to dedicated element in the list
        arg CertificateElementData: type=KeyM_CertificateElementType_Ssa_TrustModelEcuCsr_ext_specialEcu_007, direction=OUT, server-argument-impl-policy=USE-ARRAY-BASE-TYPE  # Holds a pointer to the memory location which will hold the certificate element.
        arg CertificateDataLength: type=uint32, direction=OUT  # Contains the length in bytes of certificate element.
      operation CertificateElementGetCount: possible-error=[KeyMCertificateElement_Ssa_TrustModelEcuCsr_ext_specialEcu_007/E_NOT_OK, KeyMCertificateElement_Ssa_TrustModelEcuCsr_ext_specialEcu_007/KEYM_E_KEY_CERT_SIZE_MISMATCH, KeyMCertificateElement_Ssa_TrustModelEcuCsr_ext_specialEcu_007/KEYM_E_PARAMETER_MISMATCH, KeyMCertificateElement_Ssa_TrustModelEcuCsr_ext_specialEcu_007/KEYM_E_KEY_CERT_INVALID, KeyMCertificateElement_Ssa_TrustModelEcuCsr_ext_specialEcu_007/KEYM_E_KEY_CERT_EMPTY]  # This operation returns the amount of items available for a certificate element.
        arg count: type=uint16, direction=OUT  # Number of items available for an element.
      5 x error:
        E_NOT_OK: error-code=1  # The service request failed.
        KEYM_E_KEY_CERT_SIZE_MISMATCH: error-code=4  # The service request failed. Parameter size does not match the expected value.
        KEYM_E_PARAMETER_MISMATCH: error-code=5  # The service request failed. Parameter to function does not provide the expected value.
        KEYM_E_KEY_CERT_EMPTY: error-code=10  # The service request failed. The requested key or certificate is not available, slot is empty.
        KEYM_E_KEY_CERT_INVALID: error-code=6  # The service request failed. Key or certificate is invalid and cannot be used for the operation.
    KeyMCertificateElement_Ssa_TrustModelEcuCsr_ext_extKeyUsage_007  # Service of the certificate sub module to access certificate elements.
      operation CertificateElementGet: possible-error=[KeyMCertificateElement_Ssa_TrustModelEcuCsr_ext_extKeyUsage_007/E_NOT_OK, KeyMCertificateElement_Ssa_TrustModelEcuCsr_ext_extKeyUsage_007/KEYM_E_KEY_CERT_SIZE_MISMATCH, KeyMCertificateElement_Ssa_TrustModelEcuCsr_ext_extKeyUsage_007/KEYM_E_PARAMETER_MISMATCH, KeyMCertificateElement_Ssa_TrustModelEcuCsr_ext_extKeyUsage_007/KEYM_E_KEY_CERT_INVALID, KeyMCertificateElement_Ssa_TrustModelEcuCsr_ext_extKeyUsage_007/KEYM_E_KEY_CERT_EMPTY]  # Provides the content of a specific certificate element. The certificate configuration defines how the certificate submodule can find the element, e.g. by providing the object identifier (OID). This function is used to retrieve this information if only one element is assigned to the respective OID.
        arg CertificateElementData: type=KeyM_CertificateElementType_Ssa_TrustModelEcuCsr_ext_extKeyUsage_007, direction=OUT, server-argument-impl-policy=USE-ARRAY-BASE-TYPE  # Holds a pointer to the memory location which will hold the certificate element.
        arg CertificateDataLength: type=uint32, direction=OUT  # Contains the length in bytes of certificate element.
      operation CertificateElementGetByIndex: possible-error=[KeyMCertificateElement_Ssa_TrustModelEcuCsr_ext_extKeyUsage_007/E_NOT_OK, KeyMCertificateElement_Ssa_TrustModelEcuCsr_ext_extKeyUsage_007/KEYM_E_KEY_CERT_SIZE_MISMATCH, KeyMCertificateElement_Ssa_TrustModelEcuCsr_ext_extKeyUsage_007/KEYM_E_PARAMETER_MISMATCH, KeyMCertificateElement_Ssa_TrustModelEcuCsr_ext_extKeyUsage_007/KEYM_E_KEY_CERT_INVALID, KeyMCertificateElement_Ssa_TrustModelEcuCsr_ext_extKeyUsage_007/KEYM_E_KEY_CERT_EMPTY]  # This operation provides data from a specific certificate element.
        arg Index: type=uint16, direction=IN  # This is the index to dedicated element in the list
        arg CertificateElementData: type=KeyM_CertificateElementType_Ssa_TrustModelEcuCsr_ext_extKeyUsage_007, direction=OUT, server-argument-impl-policy=USE-ARRAY-BASE-TYPE  # Holds a pointer to the memory location which will hold the certificate element.
        arg CertificateDataLength: type=uint32, direction=OUT  # Contains the length in bytes of certificate element.
      operation CertificateElementGetCount: possible-error=[KeyMCertificateElement_Ssa_TrustModelEcuCsr_ext_extKeyUsage_007/E_NOT_OK, KeyMCertificateElement_Ssa_TrustModelEcuCsr_ext_extKeyUsage_007/KEYM_E_KEY_CERT_SIZE_MISMATCH, KeyMCertificateElement_Ssa_TrustModelEcuCsr_ext_extKeyUsage_007/KEYM_E_PARAMETER_MISMATCH, KeyMCertificateElement_Ssa_TrustModelEcuCsr_ext_extKeyUsage_007/KEYM_E_KEY_CERT_INVALID, KeyMCertificateElement_Ssa_TrustModelEcuCsr_ext_extKeyUsage_007/KEYM_E_KEY_CERT_EMPTY]  # This operation returns the amount of items available for a certificate element.
        arg count: type=uint16, direction=OUT  # Number of items available for an element.
      5 x error:
        E_NOT_OK: error-code=1  # The service request failed.
        KEYM_E_KEY_CERT_SIZE_MISMATCH: error-code=4  # The service request failed. Parameter size does not match the expected value.
        KEYM_E_PARAMETER_MISMATCH: error-code=5  # The service request failed. Parameter to function does not provide the expected value.
        KEYM_E_KEY_CERT_EMPTY: error-code=10  # The service request failed. The requested key or certificate is not available, slot is empty.
        KEYM_E_KEY_CERT_INVALID: error-code=6  # The service request failed. Key or certificate is invalid and cannot be used for the operation.
    KeyMCertificateElement_Ssa_TrustModelEcuCsr_ext_extKeyUsage_oid1_007  # Service of the certificate sub module to access certificate elements.
      operation CertificateElementGet: possible-error=[KeyMCertificateElement_Ssa_TrustModelEcuCsr_ext_extKeyUsage_oid1_007/E_NOT_OK, KeyMCertificateElement_Ssa_TrustModelEcuCsr_ext_extKeyUsage_oid1_007/KEYM_E_KEY_CERT_SIZE_MISMATCH, KeyMCertificateElement_Ssa_TrustModelEcuCsr_ext_extKeyUsage_oid1_007/KEYM_E_PARAMETER_MISMATCH, KeyMCertificateElement_Ssa_TrustModelEcuCsr_ext_extKeyUsage_oid1_007/KEYM_E_KEY_CERT_INVALID, KeyMCertificateElement_Ssa_TrustModelEcuCsr_ext_extKeyUsage_oid1_007/KEYM_E_KEY_CERT_EMPTY]  # Provides the content of a specific certificate element. The certificate configuration defines how the certificate submodule can find the element, e.g. by providing the object identifier (OID). This function is used to retrieve this information if only one element is assigned to the respective OID.
        arg CertificateElementData: type=KeyM_CertificateElementType_Ssa_TrustModelEcuCsr_ext_extKeyUsage_oid1_007, direction=OUT, server-argument-impl-policy=USE-ARRAY-BASE-TYPE  # Holds a pointer to the memory location which will hold the certificate element.
        arg CertificateDataLength: type=uint32, direction=OUT  # Contains the length in bytes of certificate element.
      operation CertificateElementGetByIndex: possible-error=[KeyMCertificateElement_Ssa_TrustModelEcuCsr_ext_extKeyUsage_oid1_007/E_NOT_OK, KeyMCertificateElement_Ssa_TrustModelEcuCsr_ext_extKeyUsage_oid1_007/KEYM_E_KEY_CERT_SIZE_MISMATCH, KeyMCertificateElement_Ssa_TrustModelEcuCsr_ext_extKeyUsage_oid1_007/KEYM_E_PARAMETER_MISMATCH, KeyMCertificateElement_Ssa_TrustModelEcuCsr_ext_extKeyUsage_oid1_007/KEYM_E_KEY_CERT_INVALID, KeyMCertificateElement_Ssa_TrustModelEcuCsr_ext_extKeyUsage_oid1_007/KEYM_E_KEY_CERT_EMPTY]  # This operation provides data from a specific certificate element.
        arg Index: type=uint16, direction=IN  # This is the index to dedicated element in the list
        arg CertificateElementData: type=KeyM_CertificateElementType_Ssa_TrustModelEcuCsr_ext_extKeyUsage_oid1_007, direction=OUT, server-argument-impl-policy=USE-ARRAY-BASE-TYPE  # Holds a pointer to the memory location which will hold the certificate element.
        arg CertificateDataLength: type=uint32, direction=OUT  # Contains the length in bytes of certificate element.
      operation CertificateElementGetCount: possible-error=[KeyMCertificateElement_Ssa_TrustModelEcuCsr_ext_extKeyUsage_oid1_007/E_NOT_OK, KeyMCertificateElement_Ssa_TrustModelEcuCsr_ext_extKeyUsage_oid1_007/KEYM_E_KEY_CERT_SIZE_MISMATCH, KeyMCertificateElement_Ssa_TrustModelEcuCsr_ext_extKeyUsage_oid1_007/KEYM_E_PARAMETER_MISMATCH, KeyMCertificateElement_Ssa_TrustModelEcuCsr_ext_extKeyUsage_oid1_007/KEYM_E_KEY_CERT_INVALID, KeyMCertificateElement_Ssa_TrustModelEcuCsr_ext_extKeyUsage_oid1_007/KEYM_E_KEY_CERT_EMPTY]  # This operation returns the amount of items available for a certificate element.
        arg count: type=uint16, direction=OUT  # Number of items available for an element.
      5 x error:
        E_NOT_OK: error-code=1  # The service request failed.
        KEYM_E_KEY_CERT_SIZE_MISMATCH: error-code=4  # The service request failed. Parameter size does not match the expected value.
        KEYM_E_PARAMETER_MISMATCH: error-code=5  # The service request failed. Parameter to function does not provide the expected value.
        KEYM_E_KEY_CERT_EMPTY: error-code=10  # The service request failed. The requested key or certificate is not available, slot is empty.
        KEYM_E_KEY_CERT_INVALID: error-code=6  # The service request failed. Key or certificate is invalid and cannot be used for the operation.
    KeyMCertificateElement_Ssa_TrustModelEcuCsr_ext_extKeyUsage_oid2_007  # Service of the certificate sub module to access certificate elements.
      operation CertificateElementGet: possible-error=[KeyMCertificateElement_Ssa_TrustModelEcuCsr_ext_extKeyUsage_oid2_007/E_NOT_OK, KeyMCertificateElement_Ssa_TrustModelEcuCsr_ext_extKeyUsage_oid2_007/KEYM_E_KEY_CERT_SIZE_MISMATCH, KeyMCertificateElement_Ssa_TrustModelEcuCsr_ext_extKeyUsage_oid2_007/KEYM_E_PARAMETER_MISMATCH, KeyMCertificateElement_Ssa_TrustModelEcuCsr_ext_extKeyUsage_oid2_007/KEYM_E_KEY_CERT_INVALID, KeyMCertificateElement_Ssa_TrustModelEcuCsr_ext_extKeyUsage_oid2_007/KEYM_E_KEY_CERT_EMPTY]  # Provides the content of a specific certificate element. The certificate configuration defines how the certificate submodule can find the element, e.g. by providing the object identifier (OID). This function is used to retrieve this information if only one element is assigned to the respective OID.
        arg CertificateElementData: type=KeyM_CertificateElementType_Ssa_TrustModelEcuCsr_ext_extKeyUsage_oid2_007, direction=OUT, server-argument-impl-policy=USE-ARRAY-BASE-TYPE  # Holds a pointer to the memory location which will hold the certificate element.
        arg CertificateDataLength: type=uint32, direction=OUT  # Contains the length in bytes of certificate element.
      operation CertificateElementGetByIndex: possible-error=[KeyMCertificateElement_Ssa_TrustModelEcuCsr_ext_extKeyUsage_oid2_007/E_NOT_OK, KeyMCertificateElement_Ssa_TrustModelEcuCsr_ext_extKeyUsage_oid2_007/KEYM_E_KEY_CERT_SIZE_MISMATCH, KeyMCertificateElement_Ssa_TrustModelEcuCsr_ext_extKeyUsage_oid2_007/KEYM_E_PARAMETER_MISMATCH, KeyMCertificateElement_Ssa_TrustModelEcuCsr_ext_extKeyUsage_oid2_007/KEYM_E_KEY_CERT_INVALID, KeyMCertificateElement_Ssa_TrustModelEcuCsr_ext_extKeyUsage_oid2_007/KEYM_E_KEY_CERT_EMPTY]  # This operation provides data from a specific certificate element.
        arg Index: type=uint16, direction=IN  # This is the index to dedicated element in the list
        arg CertificateElementData: type=KeyM_CertificateElementType_Ssa_TrustModelEcuCsr_ext_extKeyUsage_oid2_007, direction=OUT, server-argument-impl-policy=USE-ARRAY-BASE-TYPE  # Holds a pointer to the memory location which will hold the certificate element.
        arg CertificateDataLength: type=uint32, direction=OUT  # Contains the length in bytes of certificate element.
      operation CertificateElementGetCount: possible-error=[KeyMCertificateElement_Ssa_TrustModelEcuCsr_ext_extKeyUsage_oid2_007/E_NOT_OK, KeyMCertificateElement_Ssa_TrustModelEcuCsr_ext_extKeyUsage_oid2_007/KEYM_E_KEY_CERT_SIZE_MISMATCH, KeyMCertificateElement_Ssa_TrustModelEcuCsr_ext_extKeyUsage_oid2_007/KEYM_E_PARAMETER_MISMATCH, KeyMCertificateElement_Ssa_TrustModelEcuCsr_ext_extKeyUsage_oid2_007/KEYM_E_KEY_CERT_INVALID, KeyMCertificateElement_Ssa_TrustModelEcuCsr_ext_extKeyUsage_oid2_007/KEYM_E_KEY_CERT_EMPTY]  # This operation returns the amount of items available for a certificate element.
        arg count: type=uint16, direction=OUT  # Number of items available for an element.
      5 x error:
        E_NOT_OK: error-code=1  # The service request failed.
        KEYM_E_KEY_CERT_SIZE_MISMATCH: error-code=4  # The service request failed. Parameter size does not match the expected value.
        KEYM_E_PARAMETER_MISMATCH: error-code=5  # The service request failed. Parameter to function does not provide the expected value.
        KEYM_E_KEY_CERT_EMPTY: error-code=10  # The service request failed. The requested key or certificate is not available, slot is empty.
        KEYM_E_KEY_CERT_INVALID: error-code=6  # The service request failed. Key or certificate is invalid and cannot be used for the operation.
    KeyMCertificateElement_Ssa_TrustModelEcuCsr_ext_extKeyUsage_oid3_007  # Service of the certificate sub module to access certificate elements.
      operation CertificateElementGet: possible-error=[KeyMCertificateElement_Ssa_TrustModelEcuCsr_ext_extKeyUsage_oid3_007/E_NOT_OK, KeyMCertificateElement_Ssa_TrustModelEcuCsr_ext_extKeyUsage_oid3_007/KEYM_E_KEY_CERT_SIZE_MISMATCH, KeyMCertificateElement_Ssa_TrustModelEcuCsr_ext_extKeyUsage_oid3_007/KEYM_E_PARAMETER_MISMATCH, KeyMCertificateElement_Ssa_TrustModelEcuCsr_ext_extKeyUsage_oid3_007/KEYM_E_KEY_CERT_INVALID, KeyMCertificateElement_Ssa_TrustModelEcuCsr_ext_extKeyUsage_oid3_007/KEYM_E_KEY_CERT_EMPTY]  # Provides the content of a specific certificate element. The certificate configuration defines how the certificate submodule can find the element, e.g. by providing the object identifier (OID). This function is used to retrieve this information if only one element is assigned to the respective OID.
        arg CertificateElementData: type=KeyM_CertificateElementType_Ssa_TrustModelEcuCsr_ext_extKeyUsage_oid3_007, direction=OUT, server-argument-impl-policy=USE-ARRAY-BASE-TYPE  # Holds a pointer to the memory location which will hold the certificate element.
        arg CertificateDataLength: type=uint32, direction=OUT  # Contains the length in bytes of certificate element.
      operation CertificateElementGetByIndex: possible-error=[KeyMCertificateElement_Ssa_TrustModelEcuCsr_ext_extKeyUsage_oid3_007/E_NOT_OK, KeyMCertificateElement_Ssa_TrustModelEcuCsr_ext_extKeyUsage_oid3_007/KEYM_E_KEY_CERT_SIZE_MISMATCH, KeyMCertificateElement_Ssa_TrustModelEcuCsr_ext_extKeyUsage_oid3_007/KEYM_E_PARAMETER_MISMATCH, KeyMCertificateElement_Ssa_TrustModelEcuCsr_ext_extKeyUsage_oid3_007/KEYM_E_KEY_CERT_INVALID, KeyMCertificateElement_Ssa_TrustModelEcuCsr_ext_extKeyUsage_oid3_007/KEYM_E_KEY_CERT_EMPTY]  # This operation provides data from a specific certificate element.
        arg Index: type=uint16, direction=IN  # This is the index to dedicated element in the list
        arg CertificateElementData: type=KeyM_CertificateElementType_Ssa_TrustModelEcuCsr_ext_extKeyUsage_oid3_007, direction=OUT, server-argument-impl-policy=USE-ARRAY-BASE-TYPE  # Holds a pointer to the memory location which will hold the certificate element.
        arg CertificateDataLength: type=uint32, direction=OUT  # Contains the length in bytes of certificate element.
      operation CertificateElementGetCount: possible-error=[KeyMCertificateElement_Ssa_TrustModelEcuCsr_ext_extKeyUsage_oid3_007/E_NOT_OK, KeyMCertificateElement_Ssa_TrustModelEcuCsr_ext_extKeyUsage_oid3_007/KEYM_E_KEY_CERT_SIZE_MISMATCH, KeyMCertificateElement_Ssa_TrustModelEcuCsr_ext_extKeyUsage_oid3_007/KEYM_E_PARAMETER_MISMATCH, KeyMCertificateElement_Ssa_TrustModelEcuCsr_ext_extKeyUsage_oid3_007/KEYM_E_KEY_CERT_INVALID, KeyMCertificateElement_Ssa_TrustModelEcuCsr_ext_extKeyUsage_oid3_007/KEYM_E_KEY_CERT_EMPTY]  # This operation returns the amount of items available for a certificate element.
        arg count: type=uint16, direction=OUT  # Number of items available for an element.
      5 x error:
        E_NOT_OK: error-code=1  # The service request failed.
        KEYM_E_KEY_CERT_SIZE_MISMATCH: error-code=4  # The service request failed. Parameter size does not match the expected value.
        KEYM_E_PARAMETER_MISMATCH: error-code=5  # The service request failed. Parameter to function does not provide the expected value.
        KEYM_E_KEY_CERT_EMPTY: error-code=10  # The service request failed. The requested key or certificate is not available, slot is empty.
        KEYM_E_KEY_CERT_INVALID: error-code=6  # The service request failed. Key or certificate is invalid and cannot be used for the operation.
    KeyMCertificate_Ssa_TrustModelRootCert  # Service of Certificate sub module
      4 x operation:
        GetCertificate: possible-error=[KeyMCertificate_Ssa_TrustModelRootCert/E_NOT_OK, KeyMCertificate_Ssa_TrustModelRootCert/KEYM_E_KEY_CERT_SIZE_MISMATCH, KeyMCertificate_Ssa_TrustModelRootCert/KEYM_E_PARAMETER_MISMATCH, KeyMCertificate_Ssa_TrustModelRootCert/KEYM_E_KEY_CERT_READ_FAIL, KeyMCertificate_Ssa_TrustModelRootCert/KEYM_E_KEY_CERT_EMPTY]  # Read certificate data from the certificate sub module
          arg Certificate: type=KeyM_CertificateType_Ssa_TrustModelRootCert, direction=OUT  # Holds a pointer to the memory location which will hold the Certificate.
        GetStatus: possible-error=KeyMCertificate_Ssa_TrustModelRootCert/E_NOT_OK  # Provides the status of a certificate.
          arg Status: type=KeyM_CertificateStatusType, direction=OUT  # Holds a pointer to the memory location which will hold the Certificate Status.
        SetCertificate: possible-error=[KeyMCertificate_Ssa_TrustModelRootCert/E_NOT_OK, KeyMCertificate_Ssa_TrustModelRootCert/KEYM_E_KEY_CERT_SIZE_MISMATCH, KeyMCertificate_Ssa_TrustModelRootCert/KEYM_E_PARAMETER_MISMATCH, KeyMCertificate_Ssa_TrustModelRootCert/KEYM_E_KEY_CERT_WRITE_FAIL]  # Provides certificate data to be processed by the certificate sub module.
          arg Certificate: type=KeyM_CertificateType_Ssa_TrustModelRootCert, direction=IN  # Holds a pointer to Certificate.
        VerifyCertificate: possible-error=[KeyMCertificate_Ssa_TrustModelRootCert/E_NOT_OK, KeyMCertificate_Ssa_TrustModelRootCert/KEYM_E_BUSY, KeyMCertificate_Ssa_TrustModelRootCert/KEYM_E_KEY_CERT_SIZE_MISMATCH, KeyMCertificate_Ssa_TrustModelRootCert/KEYM_E_PARAMETER_MISMATCH, KeyMCertificate_Ssa_TrustModelRootCert/KEYM_E_KEY_CERT_EMPTY, KeyMCertificate_Ssa_TrustModelRootCert/KEYM_E_CERT_INVALID_CHAIN_OF_TRUST]  # Verify certificate data from the certificate sub module .
      8 x error:
        E_NOT_OK: error-code=1  # The service request failed.
        KEYM_E_BUSY: error-code=2  # The service request failed. Key management is busy with other operations.
        KEYM_E_KEY_CERT_SIZE_MISMATCH: error-code=4  # The service request failed. Parameter size does not match the expected value.
        KEYM_E_PARAMETER_MISMATCH: error-code=5  # The service request failed. Parameter to function does not provide the expected value.
        KEYM_E_KEY_CERT_WRITE_FAIL: error-code=7  # The service request failed. Certificate or key write operation failed.
        KEYM_E_KEY_CERT_READ_FAIL: error-code=9  # The service request failed. Certificate or key could not be provided due to a read or permission failure.
        KEYM_E_KEY_CERT_EMPTY: error-code=10  # The service request failed. The requested key or certificate is not available, slot is empty.
        KEYM_E_CERT_INVALID_CHAIN_OF_TRUST: error-code=11  # The service request failed. Certificate verification failed - Invalid Chain of Trust.
    KeyMCertificateExtended_Ssa_TrustModelRootCert  # Services of Certificate sub module that extend the standard AUTOSAR services
      operation ServiceCertificate: possible-error=[KeyMCertificateExtended_Ssa_TrustModelRootCert/E_NOT_OK, KeyMCertificateExtended_Ssa_TrustModelRootCert/KEYM_E_BUSY, KeyMCertificateExtended_Ssa_TrustModelRootCert/KEYM_E_KEY_CERT_SIZE_MISMATCH, KeyMCertificateExtended_Ssa_TrustModelRootCert/KEYM_E_PARAMETER_MISMATCH, KeyMCertificateExtended_Ssa_TrustModelRootCert/KEYM_E_KEY_CERT_EMPTY, KeyMCertificateExtended_Ssa_TrustModelRootCert/KEYM_E_CERT_INVALID_CHAIN_OF_TRUST]  # Handle certificate operation request in the certificate sub module.
        5 x arg, all with direction=IN:
          Service: type=KeyM_ServiceCertificateType  # Provides the type of service the key manager has to perform.
          RequestData: type=KeyM_ConstDataPtrType  # Information that comes along with the request.
          RequestDataLength: type=uint32  # Length of data in the RequestData array.
          ResponseData: type=KeyM_DataPtrType  # Pointer to array in which the request response data will be stored upon request completion.
          ResponseDataLength: type=uint32  # Max number of bytes available in ResponseDataPtr.
      operation CsrElementSet: possible-error=[KeyMCertificateExtended_Ssa_TrustModelRootCert/E_NOT_OK, KeyMCertificateExtended_Ssa_TrustModelRootCert/KEYM_E_PARAMETER_MISMATCH]  # To be used before calling GenerateCertificationRequestInfo. Adds an data to the certificate for which a signing request shall be build.
        4 x arg, all with direction=IN:
          CertElementId: type=KeyM_CertElementIdType  # Element ID of the element that shall be added
          EncodingType: type=KeyM_CsrEncodingType  # Encoding type of the CSR element
          ElementData: type=KeyM_ConstDataPtrType  # Data of the element that shall be added
          ElementDataLength: type=uint32  # Length of ElementData data in the ElementData array
      6 x error:
        E_NOT_OK: error-code=1  # The service request failed.
        KEYM_E_BUSY: error-code=2  # The service request failed. Key management is busy with other operations.
        KEYM_E_KEY_CERT_SIZE_MISMATCH: error-code=4  # The service request failed. Parameter size does not match the expected value.
        KEYM_E_PARAMETER_MISMATCH: error-code=5  # The service request failed. Parameter to function does not provide the expected value.
        KEYM_E_KEY_CERT_EMPTY: error-code=10  # The service request failed. The requested key or certificate is not available, slot is empty.
        KEYM_E_CERT_INVALID_CHAIN_OF_TRUST: error-code=11  # The service request failed. Certificate verification failed - Invalid Chain of Trust.
    KeyMCertificateElement_Ssa_TrustModelRootCert_Version  # Service of the certificate sub module to access certificate elements.
      operation CertificateElementGet: possible-error=[KeyMCertificateElement_Ssa_TrustModelRootCert_Version/E_NOT_OK, KeyMCertificateElement_Ssa_TrustModelRootCert_Version/KEYM_E_KEY_CERT_SIZE_MISMATCH, KeyMCertificateElement_Ssa_TrustModelRootCert_Version/KEYM_E_PARAMETER_MISMATCH, KeyMCertificateElement_Ssa_TrustModelRootCert_Version/KEYM_E_KEY_CERT_INVALID, KeyMCertificateElement_Ssa_TrustModelRootCert_Version/KEYM_E_KEY_CERT_EMPTY]  # Provides the content of a specific certificate element. The certificate configuration defines how the certificate submodule can find the element, e.g. by providing the object identifier (OID). This function is used to retrieve this information if only one element is assigned to the respective OID.
        arg CertificateElementData: type=KeyM_CertificateElementType_Ssa_TrustModelRootCert_Version, direction=OUT, server-argument-impl-policy=USE-ARRAY-BASE-TYPE  # Holds a pointer to the memory location which will hold the certificate element.
        arg CertificateDataLength: type=uint32, direction=OUT  # Contains the length in bytes of certificate element.
      operation CertificateElementGetByIndex: possible-error=[KeyMCertificateElement_Ssa_TrustModelRootCert_Version/E_NOT_OK, KeyMCertificateElement_Ssa_TrustModelRootCert_Version/KEYM_E_KEY_CERT_SIZE_MISMATCH, KeyMCertificateElement_Ssa_TrustModelRootCert_Version/KEYM_E_PARAMETER_MISMATCH, KeyMCertificateElement_Ssa_TrustModelRootCert_Version/KEYM_E_KEY_CERT_INVALID, KeyMCertificateElement_Ssa_TrustModelRootCert_Version/KEYM_E_KEY_CERT_EMPTY]  # This operation provides data from a specific certificate element.
        arg Index: type=uint16, direction=IN  # This is the index to dedicated element in the list
        arg CertificateElementData: type=KeyM_CertificateElementType_Ssa_TrustModelRootCert_Version, direction=OUT, server-argument-impl-policy=USE-ARRAY-BASE-TYPE  # Holds a pointer to the memory location which will hold the certificate element.
        arg CertificateDataLength: type=uint32, direction=OUT  # Contains the length in bytes of certificate element.
      operation CertificateElementGetCount: possible-error=[KeyMCertificateElement_Ssa_TrustModelRootCert_Version/E_NOT_OK, KeyMCertificateElement_Ssa_TrustModelRootCert_Version/KEYM_E_KEY_CERT_SIZE_MISMATCH, KeyMCertificateElement_Ssa_TrustModelRootCert_Version/KEYM_E_PARAMETER_MISMATCH, KeyMCertificateElement_Ssa_TrustModelRootCert_Version/KEYM_E_KEY_CERT_INVALID, KeyMCertificateElement_Ssa_TrustModelRootCert_Version/KEYM_E_KEY_CERT_EMPTY]  # This operation returns the amount of items available for a certificate element.
        arg count: type=uint16, direction=OUT  # Number of items available for an element.
      5 x error:
        E_NOT_OK: error-code=1  # The service request failed.
        KEYM_E_KEY_CERT_SIZE_MISMATCH: error-code=4  # The service request failed. Parameter size does not match the expected value.
        KEYM_E_PARAMETER_MISMATCH: error-code=5  # The service request failed. Parameter to function does not provide the expected value.
        KEYM_E_KEY_CERT_EMPTY: error-code=10  # The service request failed. The requested key or certificate is not available, slot is empty.
        KEYM_E_KEY_CERT_INVALID: error-code=6  # The service request failed. Key or certificate is invalid and cannot be used for the operation.
    KeyMCertificateElement_Ssa_TrustModelRootCert_SerialNo  # Service of the certificate sub module to access certificate elements.
      operation CertificateElementGet: possible-error=[KeyMCertificateElement_Ssa_TrustModelRootCert_SerialNo/E_NOT_OK, KeyMCertificateElement_Ssa_TrustModelRootCert_SerialNo/KEYM_E_KEY_CERT_SIZE_MISMATCH, KeyMCertificateElement_Ssa_TrustModelRootCert_SerialNo/KEYM_E_PARAMETER_MISMATCH, KeyMCertificateElement_Ssa_TrustModelRootCert_SerialNo/KEYM_E_KEY_CERT_INVALID, KeyMCertificateElement_Ssa_TrustModelRootCert_SerialNo/KEYM_E_KEY_CERT_EMPTY]  # Provides the content of a specific certificate element. The certificate configuration defines how the certificate submodule can find the element, e.g. by providing the object identifier (OID). This function is used to retrieve this information if only one element is assigned to the respective OID.
        arg CertificateElementData: type=KeyM_CertificateElementType_Ssa_TrustModelRootCert_SerialNo, direction=OUT, server-argument-impl-policy=USE-ARRAY-BASE-TYPE  # Holds a pointer to the memory location which will hold the certificate element.
        arg CertificateDataLength: type=uint32, direction=OUT  # Contains the length in bytes of certificate element.
      operation CertificateElementGetByIndex: possible-error=[KeyMCertificateElement_Ssa_TrustModelRootCert_SerialNo/E_NOT_OK, KeyMCertificateElement_Ssa_TrustModelRootCert_SerialNo/KEYM_E_KEY_CERT_SIZE_MISMATCH, KeyMCertificateElement_Ssa_TrustModelRootCert_SerialNo/KEYM_E_PARAMETER_MISMATCH, KeyMCertificateElement_Ssa_TrustModelRootCert_SerialNo/KEYM_E_KEY_CERT_INVALID, KeyMCertificateElement_Ssa_TrustModelRootCert_SerialNo/KEYM_E_KEY_CERT_EMPTY]  # This operation provides data from a specific certificate element.
        arg Index: type=uint16, direction=IN  # This is the index to dedicated element in the list
        arg CertificateElementData: type=KeyM_CertificateElementType_Ssa_TrustModelRootCert_SerialNo, direction=OUT, server-argument-impl-policy=USE-ARRAY-BASE-TYPE  # Holds a pointer to the memory location which will hold the certificate element.
        arg CertificateDataLength: type=uint32, direction=OUT  # Contains the length in bytes of certificate element.
      operation CertificateElementGetCount: possible-error=[KeyMCertificateElement_Ssa_TrustModelRootCert_SerialNo/E_NOT_OK, KeyMCertificateElement_Ssa_TrustModelRootCert_SerialNo/KEYM_E_KEY_CERT_SIZE_MISMATCH, KeyMCertificateElement_Ssa_TrustModelRootCert_SerialNo/KEYM_E_PARAMETER_MISMATCH, KeyMCertificateElement_Ssa_TrustModelRootCert_SerialNo/KEYM_E_KEY_CERT_INVALID, KeyMCertificateElement_Ssa_TrustModelRootCert_SerialNo/KEYM_E_KEY_CERT_EMPTY]  # This operation returns the amount of items available for a certificate element.
        arg count: type=uint16, direction=OUT  # Number of items available for an element.
      5 x error:
        E_NOT_OK: error-code=1  # The service request failed.
        KEYM_E_KEY_CERT_SIZE_MISMATCH: error-code=4  # The service request failed. Parameter size does not match the expected value.
        KEYM_E_PARAMETER_MISMATCH: error-code=5  # The service request failed. Parameter to function does not provide the expected value.
        KEYM_E_KEY_CERT_EMPTY: error-code=10  # The service request failed. The requested key or certificate is not available, slot is empty.
        KEYM_E_KEY_CERT_INVALID: error-code=6  # The service request failed. Key or certificate is invalid and cannot be used for the operation.
    KeyMCertificateElement_Ssa_TrustModelRootCert_SigAlgoId  # Service of the certificate sub module to access certificate elements.
      operation CertificateElementGet: possible-error=[KeyMCertificateElement_Ssa_TrustModelRootCert_SigAlgoId/E_NOT_OK, KeyMCertificateElement_Ssa_TrustModelRootCert_SigAlgoId/KEYM_E_KEY_CERT_SIZE_MISMATCH, KeyMCertificateElement_Ssa_TrustModelRootCert_SigAlgoId/KEYM_E_PARAMETER_MISMATCH, KeyMCertificateElement_Ssa_TrustModelRootCert_SigAlgoId/KEYM_E_KEY_CERT_INVALID, KeyMCertificateElement_Ssa_TrustModelRootCert_SigAlgoId/KEYM_E_KEY_CERT_EMPTY]  # Provides the content of a specific certificate element. The certificate configuration defines how the certificate submodule can find the element, e.g. by providing the object identifier (OID). This function is used to retrieve this information if only one element is assigned to the respective OID.
        arg CertificateElementData: type=KeyM_CertificateElementType_Ssa_TrustModelRootCert_SigAlgoId, direction=OUT, server-argument-impl-policy=USE-ARRAY-BASE-TYPE  # Holds a pointer to the memory location which will hold the certificate element.
        arg CertificateDataLength: type=uint32, direction=OUT  # Contains the length in bytes of certificate element.
      operation CertificateElementGetByIndex: possible-error=[KeyMCertificateElement_Ssa_TrustModelRootCert_SigAlgoId/E_NOT_OK, KeyMCertificateElement_Ssa_TrustModelRootCert_SigAlgoId/KEYM_E_KEY_CERT_SIZE_MISMATCH, KeyMCertificateElement_Ssa_TrustModelRootCert_SigAlgoId/KEYM_E_PARAMETER_MISMATCH, KeyMCertificateElement_Ssa_TrustModelRootCert_SigAlgoId/KEYM_E_KEY_CERT_INVALID, KeyMCertificateElement_Ssa_TrustModelRootCert_SigAlgoId/KEYM_E_KEY_CERT_EMPTY]  # This operation provides data from a specific certificate element.
        arg Index: type=uint16, direction=IN  # This is the index to dedicated element in the list
        arg CertificateElementData: type=KeyM_CertificateElementType_Ssa_TrustModelRootCert_SigAlgoId, direction=OUT, server-argument-impl-policy=USE-ARRAY-BASE-TYPE  # Holds a pointer to the memory location which will hold the certificate element.
        arg CertificateDataLength: type=uint32, direction=OUT  # Contains the length in bytes of certificate element.
      operation CertificateElementGetCount: possible-error=[KeyMCertificateElement_Ssa_TrustModelRootCert_SigAlgoId/E_NOT_OK, KeyMCertificateElement_Ssa_TrustModelRootCert_SigAlgoId/KEYM_E_KEY_CERT_SIZE_MISMATCH, KeyMCertificateElement_Ssa_TrustModelRootCert_SigAlgoId/KEYM_E_PARAMETER_MISMATCH, KeyMCertificateElement_Ssa_TrustModelRootCert_SigAlgoId/KEYM_E_KEY_CERT_INVALID, KeyMCertificateElement_Ssa_TrustModelRootCert_SigAlgoId/KEYM_E_KEY_CERT_EMPTY]  # This operation returns the amount of items available for a certificate element.
        arg count: type=uint16, direction=OUT  # Number of items available for an element.
      5 x error:
        E_NOT_OK: error-code=1  # The service request failed.
        KEYM_E_KEY_CERT_SIZE_MISMATCH: error-code=4  # The service request failed. Parameter size does not match the expected value.
        KEYM_E_PARAMETER_MISMATCH: error-code=5  # The service request failed. Parameter to function does not provide the expected value.
        KEYM_E_KEY_CERT_EMPTY: error-code=10  # The service request failed. The requested key or certificate is not available, slot is empty.
        KEYM_E_KEY_CERT_INVALID: error-code=6  # The service request failed. Key or certificate is invalid and cannot be used for the operation.
    KeyMCertificateElement_Ssa_TrustModelRootCert_validityNotBefore  # Service of the certificate sub module to access certificate elements.
      operation CertificateElementGet: possible-error=[KeyMCertificateElement_Ssa_TrustModelRootCert_validityNotBefore/E_NOT_OK, KeyMCertificateElement_Ssa_TrustModelRootCert_validityNotBefore/KEYM_E_KEY_CERT_SIZE_MISMATCH, KeyMCertificateElement_Ssa_TrustModelRootCert_validityNotBefore/KEYM_E_PARAMETER_MISMATCH, KeyMCertificateElement_Ssa_TrustModelRootCert_validityNotBefore/KEYM_E_KEY_CERT_INVALID, KeyMCertificateElement_Ssa_TrustModelRootCert_validityNotBefore/KEYM_E_KEY_CERT_EMPTY]  # Provides the content of a specific certificate element. The certificate configuration defines how the certificate submodule can find the element, e.g. by providing the object identifier (OID). This function is used to retrieve this information if only one element is assigned to the respective OID.
        arg CertificateElementData: type=KeyM_CertificateElementType_Ssa_TrustModelRootCert_validityNotBefore, direction=OUT, server-argument-impl-policy=USE-ARRAY-BASE-TYPE  # Holds a pointer to the memory location which will hold the certificate element.
        arg CertificateDataLength: type=uint32, direction=OUT  # Contains the length in bytes of certificate element.
      operation CertificateElementGetByIndex: possible-error=[KeyMCertificateElement_Ssa_TrustModelRootCert_validityNotBefore/E_NOT_OK, KeyMCertificateElement_Ssa_TrustModelRootCert_validityNotBefore/KEYM_E_KEY_CERT_SIZE_MISMATCH, KeyMCertificateElement_Ssa_TrustModelRootCert_validityNotBefore/KEYM_E_PARAMETER_MISMATCH, KeyMCertificateElement_Ssa_TrustModelRootCert_validityNotBefore/KEYM_E_KEY_CERT_INVALID, KeyMCertificateElement_Ssa_TrustModelRootCert_validityNotBefore/KEYM_E_KEY_CERT_EMPTY]  # This operation provides data from a specific certificate element.
        arg Index: type=uint16, direction=IN  # This is the index to dedicated element in the list
        arg CertificateElementData: type=KeyM_CertificateElementType_Ssa_TrustModelRootCert_validityNotBefore, direction=OUT, server-argument-impl-policy=USE-ARRAY-BASE-TYPE  # Holds a pointer to the memory location which will hold the certificate element.
        arg CertificateDataLength: type=uint32, direction=OUT  # Contains the length in bytes of certificate element.
      operation CertificateElementGetCount: possible-error=[KeyMCertificateElement_Ssa_TrustModelRootCert_validityNotBefore/E_NOT_OK, KeyMCertificateElement_Ssa_TrustModelRootCert_validityNotBefore/KEYM_E_KEY_CERT_SIZE_MISMATCH, KeyMCertificateElement_Ssa_TrustModelRootCert_validityNotBefore/KEYM_E_PARAMETER_MISMATCH, KeyMCertificateElement_Ssa_TrustModelRootCert_validityNotBefore/KEYM_E_KEY_CERT_INVALID, KeyMCertificateElement_Ssa_TrustModelRootCert_validityNotBefore/KEYM_E_KEY_CERT_EMPTY]  # This operation returns the amount of items available for a certificate element.
        arg count: type=uint16, direction=OUT  # Number of items available for an element.
      5 x error:
        E_NOT_OK: error-code=1  # The service request failed.
        KEYM_E_KEY_CERT_SIZE_MISMATCH: error-code=4  # The service request failed. Parameter size does not match the expected value.
        KEYM_E_PARAMETER_MISMATCH: error-code=5  # The service request failed. Parameter to function does not provide the expected value.
        KEYM_E_KEY_CERT_EMPTY: error-code=10  # The service request failed. The requested key or certificate is not available, slot is empty.
        KEYM_E_KEY_CERT_INVALID: error-code=6  # The service request failed. Key or certificate is invalid and cannot be used for the operation.
    KeyMCertificateElement_Ssa_TrustModelRootCert_validityNotAfter  # Service of the certificate sub module to access certificate elements.
      operation CertificateElementGet: possible-error=[KeyMCertificateElement_Ssa_TrustModelRootCert_validityNotAfter/E_NOT_OK, KeyMCertificateElement_Ssa_TrustModelRootCert_validityNotAfter/KEYM_E_KEY_CERT_SIZE_MISMATCH, KeyMCertificateElement_Ssa_TrustModelRootCert_validityNotAfter/KEYM_E_PARAMETER_MISMATCH, KeyMCertificateElement_Ssa_TrustModelRootCert_validityNotAfter/KEYM_E_KEY_CERT_INVALID, KeyMCertificateElement_Ssa_TrustModelRootCert_validityNotAfter/KEYM_E_KEY_CERT_EMPTY]  # Provides the content of a specific certificate element. The certificate configuration defines how the certificate submodule can find the element, e.g. by providing the object identifier (OID). This function is used to retrieve this information if only one element is assigned to the respective OID.
        arg CertificateElementData: type=KeyM_CertificateElementType_Ssa_TrustModelRootCert_validityNotAfter, direction=OUT, server-argument-impl-policy=USE-ARRAY-BASE-TYPE  # Holds a pointer to the memory location which will hold the certificate element.
        arg CertificateDataLength: type=uint32, direction=OUT  # Contains the length in bytes of certificate element.
      operation CertificateElementGetByIndex: possible-error=[KeyMCertificateElement_Ssa_TrustModelRootCert_validityNotAfter/E_NOT_OK, KeyMCertificateElement_Ssa_TrustModelRootCert_validityNotAfter/KEYM_E_KEY_CERT_SIZE_MISMATCH, KeyMCertificateElement_Ssa_TrustModelRootCert_validityNotAfter/KEYM_E_PARAMETER_MISMATCH, KeyMCertificateElement_Ssa_TrustModelRootCert_validityNotAfter/KEYM_E_KEY_CERT_INVALID, KeyMCertificateElement_Ssa_TrustModelRootCert_validityNotAfter/KEYM_E_KEY_CERT_EMPTY]  # This operation provides data from a specific certificate element.
        arg Index: type=uint16, direction=IN  # This is the index to dedicated element in the list
        arg CertificateElementData: type=KeyM_CertificateElementType_Ssa_TrustModelRootCert_validityNotAfter, direction=OUT, server-argument-impl-policy=USE-ARRAY-BASE-TYPE  # Holds a pointer to the memory location which will hold the certificate element.
        arg CertificateDataLength: type=uint32, direction=OUT  # Contains the length in bytes of certificate element.
      operation CertificateElementGetCount: possible-error=[KeyMCertificateElement_Ssa_TrustModelRootCert_validityNotAfter/E_NOT_OK, KeyMCertificateElement_Ssa_TrustModelRootCert_validityNotAfter/KEYM_E_KEY_CERT_SIZE_MISMATCH, KeyMCertificateElement_Ssa_TrustModelRootCert_validityNotAfter/KEYM_E_PARAMETER_MISMATCH, KeyMCertificateElement_Ssa_TrustModelRootCert_validityNotAfter/KEYM_E_KEY_CERT_INVALID, KeyMCertificateElement_Ssa_TrustModelRootCert_validityNotAfter/KEYM_E_KEY_CERT_EMPTY]  # This operation returns the amount of items available for a certificate element.
        arg count: type=uint16, direction=OUT  # Number of items available for an element.
      5 x error:
        E_NOT_OK: error-code=1  # The service request failed.
        KEYM_E_KEY_CERT_SIZE_MISMATCH: error-code=4  # The service request failed. Parameter size does not match the expected value.
        KEYM_E_PARAMETER_MISMATCH: error-code=5  # The service request failed. Parameter to function does not provide the expected value.
        KEYM_E_KEY_CERT_EMPTY: error-code=10  # The service request failed. The requested key or certificate is not available, slot is empty.
        KEYM_E_KEY_CERT_INVALID: error-code=6  # The service request failed. Key or certificate is invalid and cannot be used for the operation.
    KeyMCertificateElement_Ssa_TrustModelRootCert_subject  # Service of the certificate sub module to access certificate elements.
      operation CertificateElementGet: possible-error=[KeyMCertificateElement_Ssa_TrustModelRootCert_subject/E_NOT_OK, KeyMCertificateElement_Ssa_TrustModelRootCert_subject/KEYM_E_KEY_CERT_SIZE_MISMATCH, KeyMCertificateElement_Ssa_TrustModelRootCert_subject/KEYM_E_PARAMETER_MISMATCH, KeyMCertificateElement_Ssa_TrustModelRootCert_subject/KEYM_E_KEY_CERT_INVALID, KeyMCertificateElement_Ssa_TrustModelRootCert_subject/KEYM_E_KEY_CERT_EMPTY]  # Provides the content of a specific certificate element. The certificate configuration defines how the certificate submodule can find the element, e.g. by providing the object identifier (OID). This function is used to retrieve this information if only one element is assigned to the respective OID.
        arg CertificateElementData: type=KeyM_CertificateElementType_Ssa_TrustModelRootCert_subject, direction=OUT, server-argument-impl-policy=USE-ARRAY-BASE-TYPE  # Holds a pointer to the memory location which will hold the certificate element.
        arg CertificateDataLength: type=uint32, direction=OUT  # Contains the length in bytes of certificate element.
      operation CertificateElementGetByIndex: possible-error=[KeyMCertificateElement_Ssa_TrustModelRootCert_subject/E_NOT_OK, KeyMCertificateElement_Ssa_TrustModelRootCert_subject/KEYM_E_KEY_CERT_SIZE_MISMATCH, KeyMCertificateElement_Ssa_TrustModelRootCert_subject/KEYM_E_PARAMETER_MISMATCH, KeyMCertificateElement_Ssa_TrustModelRootCert_subject/KEYM_E_KEY_CERT_INVALID, KeyMCertificateElement_Ssa_TrustModelRootCert_subject/KEYM_E_KEY_CERT_EMPTY]  # This operation provides data from a specific certificate element.
        arg Index: type=uint16, direction=IN  # This is the index to dedicated element in the list
        arg CertificateElementData: type=KeyM_CertificateElementType_Ssa_TrustModelRootCert_subject, direction=OUT, server-argument-impl-policy=USE-ARRAY-BASE-TYPE  # Holds a pointer to the memory location which will hold the certificate element.
        arg CertificateDataLength: type=uint32, direction=OUT  # Contains the length in bytes of certificate element.
      operation CertificateElementGetCount: possible-error=[KeyMCertificateElement_Ssa_TrustModelRootCert_subject/E_NOT_OK, KeyMCertificateElement_Ssa_TrustModelRootCert_subject/KEYM_E_KEY_CERT_SIZE_MISMATCH, KeyMCertificateElement_Ssa_TrustModelRootCert_subject/KEYM_E_PARAMETER_MISMATCH, KeyMCertificateElement_Ssa_TrustModelRootCert_subject/KEYM_E_KEY_CERT_INVALID, KeyMCertificateElement_Ssa_TrustModelRootCert_subject/KEYM_E_KEY_CERT_EMPTY]  # This operation returns the amount of items available for a certificate element.
        arg count: type=uint16, direction=OUT  # Number of items available for an element.
      5 x error:
        E_NOT_OK: error-code=1  # The service request failed.
        KEYM_E_KEY_CERT_SIZE_MISMATCH: error-code=4  # The service request failed. Parameter size does not match the expected value.
        KEYM_E_PARAMETER_MISMATCH: error-code=5  # The service request failed. Parameter to function does not provide the expected value.
        KEYM_E_KEY_CERT_EMPTY: error-code=10  # The service request failed. The requested key or certificate is not available, slot is empty.
        KEYM_E_KEY_CERT_INVALID: error-code=6  # The service request failed. Key or certificate is invalid and cannot be used for the operation.
    KeyMCertificateElement_Ssa_TrustModelRootCert_SubjectPublicKeyInfoAlgo  # Service of the certificate sub module to access certificate elements.
      operation CertificateElementGet: possible-error=[KeyMCertificateElement_Ssa_TrustModelRootCert_SubjectPublicKeyInfoAlgo/E_NOT_OK, KeyMCertificateElement_Ssa_TrustModelRootCert_SubjectPublicKeyInfoAlgo/KEYM_E_KEY_CERT_SIZE_MISMATCH, KeyMCertificateElement_Ssa_TrustModelRootCert_SubjectPublicKeyInfoAlgo/KEYM_E_PARAMETER_MISMATCH, KeyMCertificateElement_Ssa_TrustModelRootCert_SubjectPublicKeyInfoAlgo/KEYM_E_KEY_CERT_INVALID, KeyMCertificateElement_Ssa_TrustModelRootCert_SubjectPublicKeyInfoAlgo/KEYM_E_KEY_CERT_EMPTY]  # Provides the content of a specific certificate element. The certificate configuration defines how the certificate submodule can find the element, e.g. by providing the object identifier (OID). This function is used to retrieve this information if only one element is assigned to the respective OID.
        arg CertificateElementData: type=KeyM_CertificateElementType_Ssa_TrustModelRootCert_SubjectPublicKeyInfoAlgo, direction=OUT, server-argument-impl-policy=USE-ARRAY-BASE-TYPE  # Holds a pointer to the memory location which will hold the certificate element.
        arg CertificateDataLength: type=uint32, direction=OUT  # Contains the length in bytes of certificate element.
      operation CertificateElementGetByIndex: possible-error=[KeyMCertificateElement_Ssa_TrustModelRootCert_SubjectPublicKeyInfoAlgo/E_NOT_OK, KeyMCertificateElement_Ssa_TrustModelRootCert_SubjectPublicKeyInfoAlgo/KEYM_E_KEY_CERT_SIZE_MISMATCH, KeyMCertificateElement_Ssa_TrustModelRootCert_SubjectPublicKeyInfoAlgo/KEYM_E_PARAMETER_MISMATCH, KeyMCertificateElement_Ssa_TrustModelRootCert_SubjectPublicKeyInfoAlgo/KEYM_E_KEY_CERT_INVALID, KeyMCertificateElement_Ssa_TrustModelRootCert_SubjectPublicKeyInfoAlgo/KEYM_E_KEY_CERT_EMPTY]  # This operation provides data from a specific certificate element.
        arg Index: type=uint16, direction=IN  # This is the index to dedicated element in the list
        arg CertificateElementData: type=KeyM_CertificateElementType_Ssa_TrustModelRootCert_SubjectPublicKeyInfoAlgo, direction=OUT, server-argument-impl-policy=USE-ARRAY-BASE-TYPE  # Holds a pointer to the memory location which will hold the certificate element.
        arg CertificateDataLength: type=uint32, direction=OUT  # Contains the length in bytes of certificate element.
      operation CertificateElementGetCount: possible-error=[KeyMCertificateElement_Ssa_TrustModelRootCert_SubjectPublicKeyInfoAlgo/E_NOT_OK, KeyMCertificateElement_Ssa_TrustModelRootCert_SubjectPublicKeyInfoAlgo/KEYM_E_KEY_CERT_SIZE_MISMATCH, KeyMCertificateElement_Ssa_TrustModelRootCert_SubjectPublicKeyInfoAlgo/KEYM_E_PARAMETER_MISMATCH, KeyMCertificateElement_Ssa_TrustModelRootCert_SubjectPublicKeyInfoAlgo/KEYM_E_KEY_CERT_INVALID, KeyMCertificateElement_Ssa_TrustModelRootCert_SubjectPublicKeyInfoAlgo/KEYM_E_KEY_CERT_EMPTY]  # This operation returns the amount of items available for a certificate element.
        arg count: type=uint16, direction=OUT  # Number of items available for an element.
      5 x error:
        E_NOT_OK: error-code=1  # The service request failed.
        KEYM_E_KEY_CERT_SIZE_MISMATCH: error-code=4  # The service request failed. Parameter size does not match the expected value.
        KEYM_E_PARAMETER_MISMATCH: error-code=5  # The service request failed. Parameter to function does not provide the expected value.
        KEYM_E_KEY_CERT_EMPTY: error-code=10  # The service request failed. The requested key or certificate is not available, slot is empty.
        KEYM_E_KEY_CERT_INVALID: error-code=6  # The service request failed. Key or certificate is invalid and cannot be used for the operation.
    KeyMCertificateElement_Ssa_TrustModelRootCert_SubjectPublicKeyInfoKey  # Service of the certificate sub module to access certificate elements.
      operation CertificateElementGet: possible-error=[KeyMCertificateElement_Ssa_TrustModelRootCert_SubjectPublicKeyInfoKey/E_NOT_OK, KeyMCertificateElement_Ssa_TrustModelRootCert_SubjectPublicKeyInfoKey/KEYM_E_KEY_CERT_SIZE_MISMATCH, KeyMCertificateElement_Ssa_TrustModelRootCert_SubjectPublicKeyInfoKey/KEYM_E_PARAMETER_MISMATCH, KeyMCertificateElement_Ssa_TrustModelRootCert_SubjectPublicKeyInfoKey/KEYM_E_KEY_CERT_INVALID, KeyMCertificateElement_Ssa_TrustModelRootCert_SubjectPublicKeyInfoKey/KEYM_E_KEY_CERT_EMPTY]  # Provides the content of a specific certificate element. The certificate configuration defines how the certificate submodule can find the element, e.g. by providing the object identifier (OID). This function is used to retrieve this information if only one element is assigned to the respective OID.
        arg CertificateElementData: type=KeyM_CertificateElementType_Ssa_TrustModelRootCert_SubjectPublicKeyInfoKey, direction=OUT, server-argument-impl-policy=USE-ARRAY-BASE-TYPE  # Holds a pointer to the memory location which will hold the certificate element.
        arg CertificateDataLength: type=uint32, direction=OUT  # Contains the length in bytes of certificate element.
      operation CertificateElementGetByIndex: possible-error=[KeyMCertificateElement_Ssa_TrustModelRootCert_SubjectPublicKeyInfoKey/E_NOT_OK, KeyMCertificateElement_Ssa_TrustModelRootCert_SubjectPublicKeyInfoKey/KEYM_E_KEY_CERT_SIZE_MISMATCH, KeyMCertificateElement_Ssa_TrustModelRootCert_SubjectPublicKeyInfoKey/KEYM_E_PARAMETER_MISMATCH, KeyMCertificateElement_Ssa_TrustModelRootCert_SubjectPublicKeyInfoKey/KEYM_E_KEY_CERT_INVALID, KeyMCertificateElement_Ssa_TrustModelRootCert_SubjectPublicKeyInfoKey/KEYM_E_KEY_CERT_EMPTY]  # This operation provides data from a specific certificate element.
        arg Index: type=uint16, direction=IN  # This is the index to dedicated element in the list
        arg CertificateElementData: type=KeyM_CertificateElementType_Ssa_TrustModelRootCert_SubjectPublicKeyInfoKey, direction=OUT, server-argument-impl-policy=USE-ARRAY-BASE-TYPE  # Holds a pointer to the memory location which will hold the certificate element.
        arg CertificateDataLength: type=uint32, direction=OUT  # Contains the length in bytes of certificate element.
      operation CertificateElementGetCount: possible-error=[KeyMCertificateElement_Ssa_TrustModelRootCert_SubjectPublicKeyInfoKey/E_NOT_OK, KeyMCertificateElement_Ssa_TrustModelRootCert_SubjectPublicKeyInfoKey/KEYM_E_KEY_CERT_SIZE_MISMATCH, KeyMCertificateElement_Ssa_TrustModelRootCert_SubjectPublicKeyInfoKey/KEYM_E_PARAMETER_MISMATCH, KeyMCertificateElement_Ssa_TrustModelRootCert_SubjectPublicKeyInfoKey/KEYM_E_KEY_CERT_INVALID, KeyMCertificateElement_Ssa_TrustModelRootCert_SubjectPublicKeyInfoKey/KEYM_E_KEY_CERT_EMPTY]  # This operation returns the amount of items available for a certificate element.
        arg count: type=uint16, direction=OUT  # Number of items available for an element.
      5 x error:
        E_NOT_OK: error-code=1  # The service request failed.
        KEYM_E_KEY_CERT_SIZE_MISMATCH: error-code=4  # The service request failed. Parameter size does not match the expected value.
        KEYM_E_PARAMETER_MISMATCH: error-code=5  # The service request failed. Parameter to function does not provide the expected value.
        KEYM_E_KEY_CERT_EMPTY: error-code=10  # The service request failed. The requested key or certificate is not available, slot is empty.
        KEYM_E_KEY_CERT_INVALID: error-code=6  # The service request failed. Key or certificate is invalid and cannot be used for the operation.
    KeyMCertificateElement_Ssa_TrustModelRootCert_Issuer  # Service of the certificate sub module to access certificate elements.
      operation CertificateElementGet: possible-error=[KeyMCertificateElement_Ssa_TrustModelRootCert_Issuer/E_NOT_OK, KeyMCertificateElement_Ssa_TrustModelRootCert_Issuer/KEYM_E_KEY_CERT_SIZE_MISMATCH, KeyMCertificateElement_Ssa_TrustModelRootCert_Issuer/KEYM_E_PARAMETER_MISMATCH, KeyMCertificateElement_Ssa_TrustModelRootCert_Issuer/KEYM_E_KEY_CERT_INVALID, KeyMCertificateElement_Ssa_TrustModelRootCert_Issuer/KEYM_E_KEY_CERT_EMPTY]  # Provides the content of a specific certificate element. The certificate configuration defines how the certificate submodule can find the element, e.g. by providing the object identifier (OID). This function is used to retrieve this information if only one element is assigned to the respective OID.
        arg CertificateElementData: type=KeyM_CertificateElementType_Ssa_TrustModelRootCert_Issuer, direction=OUT, server-argument-impl-policy=USE-ARRAY-BASE-TYPE  # Holds a pointer to the memory location which will hold the certificate element.
        arg CertificateDataLength: type=uint32, direction=OUT  # Contains the length in bytes of certificate element.
      operation CertificateElementGetByIndex: possible-error=[KeyMCertificateElement_Ssa_TrustModelRootCert_Issuer/E_NOT_OK, KeyMCertificateElement_Ssa_TrustModelRootCert_Issuer/KEYM_E_KEY_CERT_SIZE_MISMATCH, KeyMCertificateElement_Ssa_TrustModelRootCert_Issuer/KEYM_E_PARAMETER_MISMATCH, KeyMCertificateElement_Ssa_TrustModelRootCert_Issuer/KEYM_E_KEY_CERT_INVALID, KeyMCertificateElement_Ssa_TrustModelRootCert_Issuer/KEYM_E_KEY_CERT_EMPTY]  # This operation provides data from a specific certificate element.
        arg Index: type=uint16, direction=IN  # This is the index to dedicated element in the list
        arg CertificateElementData: type=KeyM_CertificateElementType_Ssa_TrustModelRootCert_Issuer, direction=OUT, server-argument-impl-policy=USE-ARRAY-BASE-TYPE  # Holds a pointer to the memory location which will hold the certificate element.
        arg CertificateDataLength: type=uint32, direction=OUT  # Contains the length in bytes of certificate element.
      operation CertificateElementGetCount: possible-error=[KeyMCertificateElement_Ssa_TrustModelRootCert_Issuer/E_NOT_OK, KeyMCertificateElement_Ssa_TrustModelRootCert_Issuer/KEYM_E_KEY_CERT_SIZE_MISMATCH, KeyMCertificateElement_Ssa_TrustModelRootCert_Issuer/KEYM_E_PARAMETER_MISMATCH, KeyMCertificateElement_Ssa_TrustModelRootCert_Issuer/KEYM_E_KEY_CERT_INVALID, KeyMCertificateElement_Ssa_TrustModelRootCert_Issuer/KEYM_E_KEY_CERT_EMPTY]  # This operation returns the amount of items available for a certificate element.
        arg count: type=uint16, direction=OUT  # Number of items available for an element.
      5 x error:
        E_NOT_OK: error-code=1  # The service request failed.
        KEYM_E_KEY_CERT_SIZE_MISMATCH: error-code=4  # The service request failed. Parameter size does not match the expected value.
        KEYM_E_PARAMETER_MISMATCH: error-code=5  # The service request failed. Parameter to function does not provide the expected value.
        KEYM_E_KEY_CERT_EMPTY: error-code=10  # The service request failed. The requested key or certificate is not available, slot is empty.
        KEYM_E_KEY_CERT_INVALID: error-code=6  # The service request failed. Key or certificate is invalid and cannot be used for the operation.
    KeyMCertificateElement_Ssa_TrustModelRootCert_signatureAlgorithm  # Service of the certificate sub module to access certificate elements.
      operation CertificateElementGet: possible-error=[KeyMCertificateElement_Ssa_TrustModelRootCert_signatureAlgorithm/E_NOT_OK, KeyMCertificateElement_Ssa_TrustModelRootCert_signatureAlgorithm/KEYM_E_KEY_CERT_SIZE_MISMATCH, KeyMCertificateElement_Ssa_TrustModelRootCert_signatureAlgorithm/KEYM_E_PARAMETER_MISMATCH, KeyMCertificateElement_Ssa_TrustModelRootCert_signatureAlgorithm/KEYM_E_KEY_CERT_INVALID, KeyMCertificateElement_Ssa_TrustModelRootCert_signatureAlgorithm/KEYM_E_KEY_CERT_EMPTY]  # Provides the content of a specific certificate element. The certificate configuration defines how the certificate submodule can find the element, e.g. by providing the object identifier (OID). This function is used to retrieve this information if only one element is assigned to the respective OID.
        arg CertificateElementData: type=KeyM_CertificateElementType_Ssa_TrustModelRootCert_signatureAlgorithm, direction=OUT, server-argument-impl-policy=USE-ARRAY-BASE-TYPE  # Holds a pointer to the memory location which will hold the certificate element.
        arg CertificateDataLength: type=uint32, direction=OUT  # Contains the length in bytes of certificate element.
      operation CertificateElementGetByIndex: possible-error=[KeyMCertificateElement_Ssa_TrustModelRootCert_signatureAlgorithm/E_NOT_OK, KeyMCertificateElement_Ssa_TrustModelRootCert_signatureAlgorithm/KEYM_E_KEY_CERT_SIZE_MISMATCH, KeyMCertificateElement_Ssa_TrustModelRootCert_signatureAlgorithm/KEYM_E_PARAMETER_MISMATCH, KeyMCertificateElement_Ssa_TrustModelRootCert_signatureAlgorithm/KEYM_E_KEY_CERT_INVALID, KeyMCertificateElement_Ssa_TrustModelRootCert_signatureAlgorithm/KEYM_E_KEY_CERT_EMPTY]  # This operation provides data from a specific certificate element.
        arg Index: type=uint16, direction=IN  # This is the index to dedicated element in the list
        arg CertificateElementData: type=KeyM_CertificateElementType_Ssa_TrustModelRootCert_signatureAlgorithm, direction=OUT, server-argument-impl-policy=USE-ARRAY-BASE-TYPE  # Holds a pointer to the memory location which will hold the certificate element.
        arg CertificateDataLength: type=uint32, direction=OUT  # Contains the length in bytes of certificate element.
      operation CertificateElementGetCount: possible-error=[KeyMCertificateElement_Ssa_TrustModelRootCert_signatureAlgorithm/E_NOT_OK, KeyMCertificateElement_Ssa_TrustModelRootCert_signatureAlgorithm/KEYM_E_KEY_CERT_SIZE_MISMATCH, KeyMCertificateElement_Ssa_TrustModelRootCert_signatureAlgorithm/KEYM_E_PARAMETER_MISMATCH, KeyMCertificateElement_Ssa_TrustModelRootCert_signatureAlgorithm/KEYM_E_KEY_CERT_INVALID, KeyMCertificateElement_Ssa_TrustModelRootCert_signatureAlgorithm/KEYM_E_KEY_CERT_EMPTY]  # This operation returns the amount of items available for a certificate element.
        arg count: type=uint16, direction=OUT  # Number of items available for an element.
      5 x error:
        E_NOT_OK: error-code=1  # The service request failed.
        KEYM_E_KEY_CERT_SIZE_MISMATCH: error-code=4  # The service request failed. Parameter size does not match the expected value.
        KEYM_E_PARAMETER_MISMATCH: error-code=5  # The service request failed. Parameter to function does not provide the expected value.
        KEYM_E_KEY_CERT_EMPTY: error-code=10  # The service request failed. The requested key or certificate is not available, slot is empty.
        KEYM_E_KEY_CERT_INVALID: error-code=6  # The service request failed. Key or certificate is invalid and cannot be used for the operation.
    KeyMCertificateElement_Ssa_TrustModelRootCert_signatureValue  # Service of the certificate sub module to access certificate elements.
      operation CertificateElementGet: possible-error=[KeyMCertificateElement_Ssa_TrustModelRootCert_signatureValue/E_NOT_OK, KeyMCertificateElement_Ssa_TrustModelRootCert_signatureValue/KEYM_E_KEY_CERT_SIZE_MISMATCH, KeyMCertificateElement_Ssa_TrustModelRootCert_signatureValue/KEYM_E_PARAMETER_MISMATCH, KeyMCertificateElement_Ssa_TrustModelRootCert_signatureValue/KEYM_E_KEY_CERT_INVALID, KeyMCertificateElement_Ssa_TrustModelRootCert_signatureValue/KEYM_E_KEY_CERT_EMPTY]  # Provides the content of a specific certificate element. The certificate configuration defines how the certificate submodule can find the element, e.g. by providing the object identifier (OID). This function is used to retrieve this information if only one element is assigned to the respective OID.
        arg CertificateElementData: type=KeyM_CertificateElementType_Ssa_TrustModelRootCert_signatureValue, direction=OUT, server-argument-impl-policy=USE-ARRAY-BASE-TYPE  # Holds a pointer to the memory location which will hold the certificate element.
        arg CertificateDataLength: type=uint32, direction=OUT  # Contains the length in bytes of certificate element.
      operation CertificateElementGetByIndex: possible-error=[KeyMCertificateElement_Ssa_TrustModelRootCert_signatureValue/E_NOT_OK, KeyMCertificateElement_Ssa_TrustModelRootCert_signatureValue/KEYM_E_KEY_CERT_SIZE_MISMATCH, KeyMCertificateElement_Ssa_TrustModelRootCert_signatureValue/KEYM_E_PARAMETER_MISMATCH, KeyMCertificateElement_Ssa_TrustModelRootCert_signatureValue/KEYM_E_KEY_CERT_INVALID, KeyMCertificateElement_Ssa_TrustModelRootCert_signatureValue/KEYM_E_KEY_CERT_EMPTY]  # This operation provides data from a specific certificate element.
        arg Index: type=uint16, direction=IN  # This is the index to dedicated element in the list
        arg CertificateElementData: type=KeyM_CertificateElementType_Ssa_TrustModelRootCert_signatureValue, direction=OUT, server-argument-impl-policy=USE-ARRAY-BASE-TYPE  # Holds a pointer to the memory location which will hold the certificate element.
        arg CertificateDataLength: type=uint32, direction=OUT  # Contains the length in bytes of certificate element.
      operation CertificateElementGetCount: possible-error=[KeyMCertificateElement_Ssa_TrustModelRootCert_signatureValue/E_NOT_OK, KeyMCertificateElement_Ssa_TrustModelRootCert_signatureValue/KEYM_E_KEY_CERT_SIZE_MISMATCH, KeyMCertificateElement_Ssa_TrustModelRootCert_signatureValue/KEYM_E_PARAMETER_MISMATCH, KeyMCertificateElement_Ssa_TrustModelRootCert_signatureValue/KEYM_E_KEY_CERT_INVALID, KeyMCertificateElement_Ssa_TrustModelRootCert_signatureValue/KEYM_E_KEY_CERT_EMPTY]  # This operation returns the amount of items available for a certificate element.
        arg count: type=uint16, direction=OUT  # Number of items available for an element.
      5 x error:
        E_NOT_OK: error-code=1  # The service request failed.
        KEYM_E_KEY_CERT_SIZE_MISMATCH: error-code=4  # The service request failed. Parameter size does not match the expected value.
        KEYM_E_PARAMETER_MISMATCH: error-code=5  # The service request failed. Parameter to function does not provide the expected value.
        KEYM_E_KEY_CERT_EMPTY: error-code=10  # The service request failed. The requested key or certificate is not available, slot is empty.
        KEYM_E_KEY_CERT_INVALID: error-code=6  # The service request failed. Key or certificate is invalid and cannot be used for the operation.
    KeyMCertificateElement_Ssa_TrustModelRootCert_ext_subKeyId  # Service of the certificate sub module to access certificate elements.
      operation CertificateElementGet: possible-error=[KeyMCertificateElement_Ssa_TrustModelRootCert_ext_subKeyId/E_NOT_OK, KeyMCertificateElement_Ssa_TrustModelRootCert_ext_subKeyId/KEYM_E_KEY_CERT_SIZE_MISMATCH, KeyMCertificateElement_Ssa_TrustModelRootCert_ext_subKeyId/KEYM_E_PARAMETER_MISMATCH, KeyMCertificateElement_Ssa_TrustModelRootCert_ext_subKeyId/KEYM_E_KEY_CERT_INVALID, KeyMCertificateElement_Ssa_TrustModelRootCert_ext_subKeyId/KEYM_E_KEY_CERT_EMPTY]  # Provides the content of a specific certificate element. The certificate configuration defines how the certificate submodule can find the element, e.g. by providing the object identifier (OID). This function is used to retrieve this information if only one element is assigned to the respective OID.
        arg CertificateElementData: type=KeyM_CertificateElementType_Ssa_TrustModelRootCert_ext_subKeyId, direction=OUT, server-argument-impl-policy=USE-ARRAY-BASE-TYPE  # Holds a pointer to the memory location which will hold the certificate element.
        arg CertificateDataLength: type=uint32, direction=OUT  # Contains the length in bytes of certificate element.
      operation CertificateElementGetByIndex: possible-error=[KeyMCertificateElement_Ssa_TrustModelRootCert_ext_subKeyId/E_NOT_OK, KeyMCertificateElement_Ssa_TrustModelRootCert_ext_subKeyId/KEYM_E_KEY_CERT_SIZE_MISMATCH, KeyMCertificateElement_Ssa_TrustModelRootCert_ext_subKeyId/KEYM_E_PARAMETER_MISMATCH, KeyMCertificateElement_Ssa_TrustModelRootCert_ext_subKeyId/KEYM_E_KEY_CERT_INVALID, KeyMCertificateElement_Ssa_TrustModelRootCert_ext_subKeyId/KEYM_E_KEY_CERT_EMPTY]  # This operation provides data from a specific certificate element.
        arg Index: type=uint16, direction=IN  # This is the index to dedicated element in the list
        arg CertificateElementData: type=KeyM_CertificateElementType_Ssa_TrustModelRootCert_ext_subKeyId, direction=OUT, server-argument-impl-policy=USE-ARRAY-BASE-TYPE  # Holds a pointer to the memory location which will hold the certificate element.
        arg CertificateDataLength: type=uint32, direction=OUT  # Contains the length in bytes of certificate element.
      operation CertificateElementGetCount: possible-error=[KeyMCertificateElement_Ssa_TrustModelRootCert_ext_subKeyId/E_NOT_OK, KeyMCertificateElement_Ssa_TrustModelRootCert_ext_subKeyId/KEYM_E_KEY_CERT_SIZE_MISMATCH, KeyMCertificateElement_Ssa_TrustModelRootCert_ext_subKeyId/KEYM_E_PARAMETER_MISMATCH, KeyMCertificateElement_Ssa_TrustModelRootCert_ext_subKeyId/KEYM_E_KEY_CERT_INVALID, KeyMCertificateElement_Ssa_TrustModelRootCert_ext_subKeyId/KEYM_E_KEY_CERT_EMPTY]  # This operation returns the amount of items available for a certificate element.
        arg count: type=uint16, direction=OUT  # Number of items available for an element.
      5 x error:
        E_NOT_OK: error-code=1  # The service request failed.
        KEYM_E_KEY_CERT_SIZE_MISMATCH: error-code=4  # The service request failed. Parameter size does not match the expected value.
        KEYM_E_PARAMETER_MISMATCH: error-code=5  # The service request failed. Parameter to function does not provide the expected value.
        KEYM_E_KEY_CERT_EMPTY: error-code=10  # The service request failed. The requested key or certificate is not available, slot is empty.
        KEYM_E_KEY_CERT_INVALID: error-code=6  # The service request failed. Key or certificate is invalid and cannot be used for the operation.
    KeyMCertificateElement_Ssa_TrustModelRootCert_ext_basicConstraints  # Service of the certificate sub module to access certificate elements.
      operation CertificateElementGet: possible-error=[KeyMCertificateElement_Ssa_TrustModelRootCert_ext_basicConstraints/E_NOT_OK, KeyMCertificateElement_Ssa_TrustModelRootCert_ext_basicConstraints/KEYM_E_KEY_CERT_SIZE_MISMATCH, KeyMCertificateElement_Ssa_TrustModelRootCert_ext_basicConstraints/KEYM_E_PARAMETER_MISMATCH, KeyMCertificateElement_Ssa_TrustModelRootCert_ext_basicConstraints/KEYM_E_KEY_CERT_INVALID, KeyMCertificateElement_Ssa_TrustModelRootCert_ext_basicConstraints/KEYM_E_KEY_CERT_EMPTY]  # Provides the content of a specific certificate element. The certificate configuration defines how the certificate submodule can find the element, e.g. by providing the object identifier (OID). This function is used to retrieve this information if only one element is assigned to the respective OID.
        arg CertificateElementData: type=KeyM_CertificateElementType_Ssa_TrustModelRootCert_ext_basicConstraints, direction=OUT, server-argument-impl-policy=USE-ARRAY-BASE-TYPE  # Holds a pointer to the memory location which will hold the certificate element.
        arg CertificateDataLength: type=uint32, direction=OUT  # Contains the length in bytes of certificate element.
      operation CertificateElementGetByIndex: possible-error=[KeyMCertificateElement_Ssa_TrustModelRootCert_ext_basicConstraints/E_NOT_OK, KeyMCertificateElement_Ssa_TrustModelRootCert_ext_basicConstraints/KEYM_E_KEY_CERT_SIZE_MISMATCH, KeyMCertificateElement_Ssa_TrustModelRootCert_ext_basicConstraints/KEYM_E_PARAMETER_MISMATCH, KeyMCertificateElement_Ssa_TrustModelRootCert_ext_basicConstraints/KEYM_E_KEY_CERT_INVALID, KeyMCertificateElement_Ssa_TrustModelRootCert_ext_basicConstraints/KEYM_E_KEY_CERT_EMPTY]  # This operation provides data from a specific certificate element.
        arg Index: type=uint16, direction=IN  # This is the index to dedicated element in the list
        arg CertificateElementData: type=KeyM_CertificateElementType_Ssa_TrustModelRootCert_ext_basicConstraints, direction=OUT, server-argument-impl-policy=USE-ARRAY-BASE-TYPE  # Holds a pointer to the memory location which will hold the certificate element.
        arg CertificateDataLength: type=uint32, direction=OUT  # Contains the length in bytes of certificate element.
      operation CertificateElementGetCount: possible-error=[KeyMCertificateElement_Ssa_TrustModelRootCert_ext_basicConstraints/E_NOT_OK, KeyMCertificateElement_Ssa_TrustModelRootCert_ext_basicConstraints/KEYM_E_KEY_CERT_SIZE_MISMATCH, KeyMCertificateElement_Ssa_TrustModelRootCert_ext_basicConstraints/KEYM_E_PARAMETER_MISMATCH, KeyMCertificateElement_Ssa_TrustModelRootCert_ext_basicConstraints/KEYM_E_KEY_CERT_INVALID, KeyMCertificateElement_Ssa_TrustModelRootCert_ext_basicConstraints/KEYM_E_KEY_CERT_EMPTY]  # This operation returns the amount of items available for a certificate element.
        arg count: type=uint16, direction=OUT  # Number of items available for an element.
      5 x error:
        E_NOT_OK: error-code=1  # The service request failed.
        KEYM_E_KEY_CERT_SIZE_MISMATCH: error-code=4  # The service request failed. Parameter size does not match the expected value.
        KEYM_E_PARAMETER_MISMATCH: error-code=5  # The service request failed. Parameter to function does not provide the expected value.
        KEYM_E_KEY_CERT_EMPTY: error-code=10  # The service request failed. The requested key or certificate is not available, slot is empty.
        KEYM_E_KEY_CERT_INVALID: error-code=6  # The service request failed. Key or certificate is invalid and cannot be used for the operation.
    KeyMCertificateElement_Ssa_TrustModelRootCert_ext_keyUsage  # Service of the certificate sub module to access certificate elements.
      operation CertificateElementGet: possible-error=[KeyMCertificateElement_Ssa_TrustModelRootCert_ext_keyUsage/E_NOT_OK, KeyMCertificateElement_Ssa_TrustModelRootCert_ext_keyUsage/KEYM_E_KEY_CERT_SIZE_MISMATCH, KeyMCertificateElement_Ssa_TrustModelRootCert_ext_keyUsage/KEYM_E_PARAMETER_MISMATCH, KeyMCertificateElement_Ssa_TrustModelRootCert_ext_keyUsage/KEYM_E_KEY_CERT_INVALID, KeyMCertificateElement_Ssa_TrustModelRootCert_ext_keyUsage/KEYM_E_KEY_CERT_EMPTY]  # Provides the content of a specific certificate element. The certificate configuration defines how the certificate submodule can find the element, e.g. by providing the object identifier (OID). This function is used to retrieve this information if only one element is assigned to the respective OID.
        arg CertificateElementData: type=KeyM_CertificateElementType_Ssa_TrustModelRootCert_ext_keyUsage, direction=OUT, server-argument-impl-policy=USE-ARRAY-BASE-TYPE  # Holds a pointer to the memory location which will hold the certificate element.
        arg CertificateDataLength: type=uint32, direction=OUT  # Contains the length in bytes of certificate element.
      operation CertificateElementGetByIndex: possible-error=[KeyMCertificateElement_Ssa_TrustModelRootCert_ext_keyUsage/E_NOT_OK, KeyMCertificateElement_Ssa_TrustModelRootCert_ext_keyUsage/KEYM_E_KEY_CERT_SIZE_MISMATCH, KeyMCertificateElement_Ssa_TrustModelRootCert_ext_keyUsage/KEYM_E_PARAMETER_MISMATCH, KeyMCertificateElement_Ssa_TrustModelRootCert_ext_keyUsage/KEYM_E_KEY_CERT_INVALID, KeyMCertificateElement_Ssa_TrustModelRootCert_ext_keyUsage/KEYM_E_KEY_CERT_EMPTY]  # This operation provides data from a specific certificate element.
        arg Index: type=uint16, direction=IN  # This is the index to dedicated element in the list
        arg CertificateElementData: type=KeyM_CertificateElementType_Ssa_TrustModelRootCert_ext_keyUsage, direction=OUT, server-argument-impl-policy=USE-ARRAY-BASE-TYPE  # Holds a pointer to the memory location which will hold the certificate element.
        arg CertificateDataLength: type=uint32, direction=OUT  # Contains the length in bytes of certificate element.
      operation CertificateElementGetCount: possible-error=[KeyMCertificateElement_Ssa_TrustModelRootCert_ext_keyUsage/E_NOT_OK, KeyMCertificateElement_Ssa_TrustModelRootCert_ext_keyUsage/KEYM_E_KEY_CERT_SIZE_MISMATCH, KeyMCertificateElement_Ssa_TrustModelRootCert_ext_keyUsage/KEYM_E_PARAMETER_MISMATCH, KeyMCertificateElement_Ssa_TrustModelRootCert_ext_keyUsage/KEYM_E_KEY_CERT_INVALID, KeyMCertificateElement_Ssa_TrustModelRootCert_ext_keyUsage/KEYM_E_KEY_CERT_EMPTY]  # This operation returns the amount of items available for a certificate element.
        arg count: type=uint16, direction=OUT  # Number of items available for an element.
      5 x error:
        E_NOT_OK: error-code=1  # The service request failed.
        KEYM_E_KEY_CERT_SIZE_MISMATCH: error-code=4  # The service request failed. Parameter size does not match the expected value.
        KEYM_E_PARAMETER_MISMATCH: error-code=5  # The service request failed. Parameter to function does not provide the expected value.
        KEYM_E_KEY_CERT_EMPTY: error-code=10  # The service request failed. The requested key or certificate is not available, slot is empty.
        KEYM_E_KEY_CERT_INVALID: error-code=6  # The service request failed. Key or certificate is invalid and cannot be used for the operation.
    KeyMCertificateElement_Ssa_TrustModelRootCert_ext_pkiRole  # Service of the certificate sub module to access certificate elements.
      operation CertificateElementGet: possible-error=[KeyMCertificateElement_Ssa_TrustModelRootCert_ext_pkiRole/E_NOT_OK, KeyMCertificateElement_Ssa_TrustModelRootCert_ext_pkiRole/KEYM_E_KEY_CERT_SIZE_MISMATCH, KeyMCertificateElement_Ssa_TrustModelRootCert_ext_pkiRole/KEYM_E_PARAMETER_MISMATCH, KeyMCertificateElement_Ssa_TrustModelRootCert_ext_pkiRole/KEYM_E_KEY_CERT_INVALID, KeyMCertificateElement_Ssa_TrustModelRootCert_ext_pkiRole/KEYM_E_KEY_CERT_EMPTY]  # Provides the content of a specific certificate element. The certificate configuration defines how the certificate submodule can find the element, e.g. by providing the object identifier (OID). This function is used to retrieve this information if only one element is assigned to the respective OID.
        arg CertificateElementData: type=KeyM_CertificateElementType_Ssa_TrustModelRootCert_ext_pkiRole, direction=OUT, server-argument-impl-policy=USE-ARRAY-BASE-TYPE  # Holds a pointer to the memory location which will hold the certificate element.
        arg CertificateDataLength: type=uint32, direction=OUT  # Contains the length in bytes of certificate element.
      operation CertificateElementGetByIndex: possible-error=[KeyMCertificateElement_Ssa_TrustModelRootCert_ext_pkiRole/E_NOT_OK, KeyMCertificateElement_Ssa_TrustModelRootCert_ext_pkiRole/KEYM_E_KEY_CERT_SIZE_MISMATCH, KeyMCertificateElement_Ssa_TrustModelRootCert_ext_pkiRole/KEYM_E_PARAMETER_MISMATCH, KeyMCertificateElement_Ssa_TrustModelRootCert_ext_pkiRole/KEYM_E_KEY_CERT_INVALID, KeyMCertificateElement_Ssa_TrustModelRootCert_ext_pkiRole/KEYM_E_KEY_CERT_EMPTY]  # This operation provides data from a specific certificate element.
        arg Index: type=uint16, direction=IN  # This is the index to dedicated element in the list
        arg CertificateElementData: type=KeyM_CertificateElementType_Ssa_TrustModelRootCert_ext_pkiRole, direction=OUT, server-argument-impl-policy=USE-ARRAY-BASE-TYPE  # Holds a pointer to the memory location which will hold the certificate element.
        arg CertificateDataLength: type=uint32, direction=OUT  # Contains the length in bytes of certificate element.
      operation CertificateElementGetCount: possible-error=[KeyMCertificateElement_Ssa_TrustModelRootCert_ext_pkiRole/E_NOT_OK, KeyMCertificateElement_Ssa_TrustModelRootCert_ext_pkiRole/KEYM_E_KEY_CERT_SIZE_MISMATCH, KeyMCertificateElement_Ssa_TrustModelRootCert_ext_pkiRole/KEYM_E_PARAMETER_MISMATCH, KeyMCertificateElement_Ssa_TrustModelRootCert_ext_pkiRole/KEYM_E_KEY_CERT_INVALID, KeyMCertificateElement_Ssa_TrustModelRootCert_ext_pkiRole/KEYM_E_KEY_CERT_EMPTY]  # This operation returns the amount of items available for a certificate element.
        arg count: type=uint16, direction=OUT  # Number of items available for an element.
      5 x error:
        E_NOT_OK: error-code=1  # The service request failed.
        KEYM_E_KEY_CERT_SIZE_MISMATCH: error-code=4  # The service request failed. Parameter size does not match the expected value.
        KEYM_E_PARAMETER_MISMATCH: error-code=5  # The service request failed. Parameter to function does not provide the expected value.
        KEYM_E_KEY_CERT_EMPTY: error-code=10  # The service request failed. The requested key or certificate is not available, slot is empty.
        KEYM_E_KEY_CERT_INVALID: error-code=6  # The service request failed. Key or certificate is invalid and cannot be used for the operation.
    KeyMCertificateElement_Ssa_TrustModelEcuCert_ext_pkiRole_006  # Service of the certificate sub module to access certificate elements.
      operation CertificateElementGet: possible-error=[KeyMCertificateElement_Ssa_TrustModelEcuCert_ext_pkiRole_006/E_NOT_OK, KeyMCertificateElement_Ssa_TrustModelEcuCert_ext_pkiRole_006/KEYM_E_KEY_CERT_SIZE_MISMATCH, KeyMCertificateElement_Ssa_TrustModelEcuCert_ext_pkiRole_006/KEYM_E_PARAMETER_MISMATCH, KeyMCertificateElement_Ssa_TrustModelEcuCert_ext_pkiRole_006/KEYM_E_KEY_CERT_INVALID, KeyMCertificateElement_Ssa_TrustModelEcuCert_ext_pkiRole_006/KEYM_E_KEY_CERT_EMPTY]  # Provides the content of a specific certificate element. The certificate configuration defines how the certificate submodule can find the element, e.g. by providing the object identifier (OID). This function is used to retrieve this information if only one element is assigned to the respective OID.
        arg CertificateElementData: type=KeyM_CertificateElementType_Ssa_TrustModelEcuCert_ext_pkiRole_006, direction=OUT, server-argument-impl-policy=USE-ARRAY-BASE-TYPE  # Holds a pointer to the memory location which will hold the certificate element.
        arg CertificateDataLength: type=uint32, direction=OUT  # Contains the length in bytes of certificate element.
      operation CertificateElementGetByIndex: possible-error=[KeyMCertificateElement_Ssa_TrustModelEcuCert_ext_pkiRole_006/E_NOT_OK, KeyMCertificateElement_Ssa_TrustModelEcuCert_ext_pkiRole_006/KEYM_E_KEY_CERT_SIZE_MISMATCH, KeyMCertificateElement_Ssa_TrustModelEcuCert_ext_pkiRole_006/KEYM_E_PARAMETER_MISMATCH, KeyMCertificateElement_Ssa_TrustModelEcuCert_ext_pkiRole_006/KEYM_E_KEY_CERT_INVALID, KeyMCertificateElement_Ssa_TrustModelEcuCert_ext_pkiRole_006/KEYM_E_KEY_CERT_EMPTY]  # This operation provides data from a specific certificate element.
        arg Index: type=uint16, direction=IN  # This is the index to dedicated element in the list
        arg CertificateElementData: type=KeyM_CertificateElementType_Ssa_TrustModelEcuCert_ext_pkiRole_006, direction=OUT, server-argument-impl-policy=USE-ARRAY-BASE-TYPE  # Holds a pointer to the memory location which will hold the certificate element.
        arg CertificateDataLength: type=uint32, direction=OUT  # Contains the length in bytes of certificate element.
      operation CertificateElementGetCount: possible-error=[KeyMCertificateElement_Ssa_TrustModelEcuCert_ext_pkiRole_006/E_NOT_OK, KeyMCertificateElement_Ssa_TrustModelEcuCert_ext_pkiRole_006/KEYM_E_KEY_CERT_SIZE_MISMATCH, KeyMCertificateElement_Ssa_TrustModelEcuCert_ext_pkiRole_006/KEYM_E_PARAMETER_MISMATCH, KeyMCertificateElement_Ssa_TrustModelEcuCert_ext_pkiRole_006/KEYM_E_KEY_CERT_INVALID, KeyMCertificateElement_Ssa_TrustModelEcuCert_ext_pkiRole_006/KEYM_E_KEY_CERT_EMPTY]  # This operation returns the amount of items available for a certificate element.
        arg count: type=uint16, direction=OUT  # Number of items available for an element.
      5 x error:
        E_NOT_OK: error-code=1  # The service request failed.
        KEYM_E_KEY_CERT_SIZE_MISMATCH: error-code=4  # The service request failed. Parameter size does not match the expected value.
        KEYM_E_PARAMETER_MISMATCH: error-code=5  # The service request failed. Parameter to function does not provide the expected value.
        KEYM_E_KEY_CERT_EMPTY: error-code=10  # The service request failed. The requested key or certificate is not available, slot is empty.
        KEYM_E_KEY_CERT_INVALID: error-code=6  # The service request failed. Key or certificate is invalid and cannot be used for the operation.
    KeyMCertificateElement_Ssa_TrustModelIntermediatePeerCert_ext_pkiRole_005  # Service of the certificate sub module to access certificate elements.
      operation CertificateElementGet: possible-error=[KeyMCertificateElement_Ssa_TrustModelIntermediatePeerCert_ext_pkiRole_005/E_NOT_OK, KeyMCertificateElement_Ssa_TrustModelIntermediatePeerCert_ext_pkiRole_005/KEYM_E_KEY_CERT_SIZE_MISMATCH, KeyMCertificateElement_Ssa_TrustModelIntermediatePeerCert_ext_pkiRole_005/KEYM_E_PARAMETER_MISMATCH, KeyMCertificateElement_Ssa_TrustModelIntermediatePeerCert_ext_pkiRole_005/KEYM_E_KEY_CERT_INVALID, KeyMCertificateElement_Ssa_TrustModelIntermediatePeerCert_ext_pkiRole_005/KEYM_E_KEY_CERT_EMPTY]  # Provides the content of a specific certificate element. The certificate configuration defines how the certificate submodule can find the element, e.g. by providing the object identifier (OID). This function is used to retrieve this information if only one element is assigned to the respective OID.
        arg CertificateElementData: type=KeyM_CertificateElementType_Ssa_TrustModelIntermediatePeerCert_ext_pkiRole_005, direction=OUT, server-argument-impl-policy=USE-ARRAY-BASE-TYPE  # Holds a pointer to the memory location which will hold the certificate element.
        arg CertificateDataLength: type=uint32, direction=OUT  # Contains the length in bytes of certificate element.
      operation CertificateElementGetByIndex: possible-error=[KeyMCertificateElement_Ssa_TrustModelIntermediatePeerCert_ext_pkiRole_005/E_NOT_OK, KeyMCertificateElement_Ssa_TrustModelIntermediatePeerCert_ext_pkiRole_005/KEYM_E_KEY_CERT_SIZE_MISMATCH, KeyMCertificateElement_Ssa_TrustModelIntermediatePeerCert_ext_pkiRole_005/KEYM_E_PARAMETER_MISMATCH, KeyMCertificateElement_Ssa_TrustModelIntermediatePeerCert_ext_pkiRole_005/KEYM_E_KEY_CERT_INVALID, KeyMCertificateElement_Ssa_TrustModelIntermediatePeerCert_ext_pkiRole_005/KEYM_E_KEY_CERT_EMPTY]  # This operation provides data from a specific certificate element.
        arg Index: type=uint16, direction=IN  # This is the index to dedicated element in the list
        arg CertificateElementData: type=KeyM_CertificateElementType_Ssa_TrustModelIntermediatePeerCert_ext_pkiRole_005, direction=OUT, server-argument-impl-policy=USE-ARRAY-BASE-TYPE  # Holds a pointer to the memory location which will hold the certificate element.
        arg CertificateDataLength: type=uint32, direction=OUT  # Contains the length in bytes of certificate element.
      operation CertificateElementGetCount: possible-error=[KeyMCertificateElement_Ssa_TrustModelIntermediatePeerCert_ext_pkiRole_005/E_NOT_OK, KeyMCertificateElement_Ssa_TrustModelIntermediatePeerCert_ext_pkiRole_005/KEYM_E_KEY_CERT_SIZE_MISMATCH, KeyMCertificateElement_Ssa_TrustModelIntermediatePeerCert_ext_pkiRole_005/KEYM_E_PARAMETER_MISMATCH, KeyMCertificateElement_Ssa_TrustModelIntermediatePeerCert_ext_pkiRole_005/KEYM_E_KEY_CERT_INVALID, KeyMCertificateElement_Ssa_TrustModelIntermediatePeerCert_ext_pkiRole_005/KEYM_E_KEY_CERT_EMPTY]  # This operation returns the amount of items available for a certificate element.
        arg count: type=uint16, direction=OUT  # Number of items available for an element.
      5 x error:
        E_NOT_OK: error-code=1  # The service request failed.
        KEYM_E_KEY_CERT_SIZE_MISMATCH: error-code=4  # The service request failed. Parameter size does not match the expected value.
        KEYM_E_PARAMETER_MISMATCH: error-code=5  # The service request failed. Parameter to function does not provide the expected value.
        KEYM_E_KEY_CERT_EMPTY: error-code=10  # The service request failed. The requested key or certificate is not available, slot is empty.
        KEYM_E_KEY_CERT_INVALID: error-code=6  # The service request failed. Key or certificate is invalid and cannot be used for the operation.
    KeyMCertificateElement_Ssa_TrustModelRootCert_ext_authKeyId_009  # Service of the certificate sub module to access certificate elements.
      operation CertificateElementGet: possible-error=[KeyMCertificateElement_Ssa_TrustModelRootCert_ext_authKeyId_009/E_NOT_OK, KeyMCertificateElement_Ssa_TrustModelRootCert_ext_authKeyId_009/KEYM_E_KEY_CERT_SIZE_MISMATCH, KeyMCertificateElement_Ssa_TrustModelRootCert_ext_authKeyId_009/KEYM_E_PARAMETER_MISMATCH, KeyMCertificateElement_Ssa_TrustModelRootCert_ext_authKeyId_009/KEYM_E_KEY_CERT_INVALID, KeyMCertificateElement_Ssa_TrustModelRootCert_ext_authKeyId_009/KEYM_E_KEY_CERT_EMPTY]  # Provides the content of a specific certificate element. The certificate configuration defines how the certificate submodule can find the element, e.g. by providing the object identifier (OID). This function is used to retrieve this information if only one element is assigned to the respective OID.
        arg CertificateElementData: type=KeyM_CertificateElementType_Ssa_TrustModelRootCert_ext_authKeyId_009, direction=OUT, server-argument-impl-policy=USE-ARRAY-BASE-TYPE  # Holds a pointer to the memory location which will hold the certificate element.
        arg CertificateDataLength: type=uint32, direction=OUT  # Contains the length in bytes of certificate element.
      operation CertificateElementGetByIndex: possible-error=[KeyMCertificateElement_Ssa_TrustModelRootCert_ext_authKeyId_009/E_NOT_OK, KeyMCertificateElement_Ssa_TrustModelRootCert_ext_authKeyId_009/KEYM_E_KEY_CERT_SIZE_MISMATCH, KeyMCertificateElement_Ssa_TrustModelRootCert_ext_authKeyId_009/KEYM_E_PARAMETER_MISMATCH, KeyMCertificateElement_Ssa_TrustModelRootCert_ext_authKeyId_009/KEYM_E_KEY_CERT_INVALID, KeyMCertificateElement_Ssa_TrustModelRootCert_ext_authKeyId_009/KEYM_E_KEY_CERT_EMPTY]  # This operation provides data from a specific certificate element.
        arg Index: type=uint16, direction=IN  # This is the index to dedicated element in the list
        arg CertificateElementData: type=KeyM_CertificateElementType_Ssa_TrustModelRootCert_ext_authKeyId_009, direction=OUT, server-argument-impl-policy=USE-ARRAY-BASE-TYPE  # Holds a pointer to the memory location which will hold the certificate element.
        arg CertificateDataLength: type=uint32, direction=OUT  # Contains the length in bytes of certificate element.
      operation CertificateElementGetCount: possible-error=[KeyMCertificateElement_Ssa_TrustModelRootCert_ext_authKeyId_009/E_NOT_OK, KeyMCertificateElement_Ssa_TrustModelRootCert_ext_authKeyId_009/KEYM_E_KEY_CERT_SIZE_MISMATCH, KeyMCertificateElement_Ssa_TrustModelRootCert_ext_authKeyId_009/KEYM_E_PARAMETER_MISMATCH, KeyMCertificateElement_Ssa_TrustModelRootCert_ext_authKeyId_009/KEYM_E_KEY_CERT_INVALID, KeyMCertificateElement_Ssa_TrustModelRootCert_ext_authKeyId_009/KEYM_E_KEY_CERT_EMPTY]  # This operation returns the amount of items available for a certificate element.
        arg count: type=uint16, direction=OUT  # Number of items available for an element.
      5 x error:
        E_NOT_OK: error-code=1  # The service request failed.
        KEYM_E_KEY_CERT_SIZE_MISMATCH: error-code=4  # The service request failed. Parameter size does not match the expected value.
        KEYM_E_PARAMETER_MISMATCH: error-code=5  # The service request failed. Parameter to function does not provide the expected value.
        KEYM_E_KEY_CERT_EMPTY: error-code=10  # The service request failed. The requested key or certificate is not available, slot is empty.
        KEYM_E_KEY_CERT_INVALID: error-code=6  # The service request failed. Key or certificate is invalid and cannot be used for the operation.
    KeyMServiceCertificate  # This service interface provides the certificate management operation.
      operation ServiceCertificate: possible-error=[KeyMServiceCertificate/E_NOT_OK, KeyMServiceCertificate/KEYM_E_BUSY, KeyMServiceCertificate/KEYM_E_KEY_CERT_SIZE_MISMATCH, KeyMServiceCertificate/KEYM_E_PARAMETER_MISMATCH]  # Operation to execute the certificate management operation.
        7 x arg, all with direction=IN:
          Service: type=KeyM_ServiceCertificateType  # Provides the type of service the key manager has to perform
          CertNamePtr: type=dtRef_const_VOID  # Points to an array that defines the name of the certificate to be serviced
          CertNameLength: type=uint32  # Specifies the number of bytes in CertNamePtr. The value 0 indicates that no CertNamePtr is provided within this function.
          RequestData: type=dtRef_const_VOID  # Information that comes along with the request
          RequestDataLength: type=uint32  # Length of data in the RequestData array
          ResponseData: type=dtRef_VOID  # Data returned by the service
          ResponseDataLength: type=uint32  # Max number of bytes available in ResponseDataPtr
      4 x error:
        E_NOT_OK: error-code=1  # The service request failed.
        KEYM_E_BUSY: error-code=2  # The service request failed. Key management is busy with other operations.
        KEYM_E_KEY_CERT_SIZE_MISMATCH: error-code=4  # The service request failed. Parameter size does not match the expected value.
        KEYM_E_PARAMETER_MISMATCH: error-code=5  # The service request failed. Parameter to function does not provide the expected value.
    KeyMServiceCertificateByCertId  # This service interface provides the certificate management operation.
      operation ServiceCertificateByCertId: possible-error=[KeyMServiceCertificateByCertId/E_NOT_OK, KeyMServiceCertificateByCertId/KEYM_E_BUSY, KeyMServiceCertificateByCertId/KEYM_E_KEY_CERT_SIZE_MISMATCH, KeyMServiceCertificateByCertId/KEYM_E_PARAMETER_MISMATCH]  # Operation to execute the certificate management operation.
        5 x arg, all with direction=IN:
          Service: type=KeyM_ServiceCertificateType  # Provides the type of service the key manager has to perform
          RequestData: type=dtRef_const_VOID  # Information that comes along with the request
          RequestDataLength: type=uint32  # Length of data in the RequestData array
          ResponseData: type=dtRef_VOID  # Data returned by the service
          ResponseDataLength: type=uint32  # Max number of bytes available in ResponseDataPtr
      4 x error:
        E_NOT_OK: error-code=1  # The service request failed.
        KEYM_E_BUSY: error-code=2  # The service request failed. Key management is busy with other operations.
        KEYM_E_KEY_CERT_SIZE_MISMATCH: error-code=4  # The service request failed. Parameter size does not match the expected value.
        KEYM_E_PARAMETER_MISMATCH: error-code=5  # The service request failed. Parameter to function does not provide the expected value.
package /MICROSAR/KeyM_swc/ComponentTypes
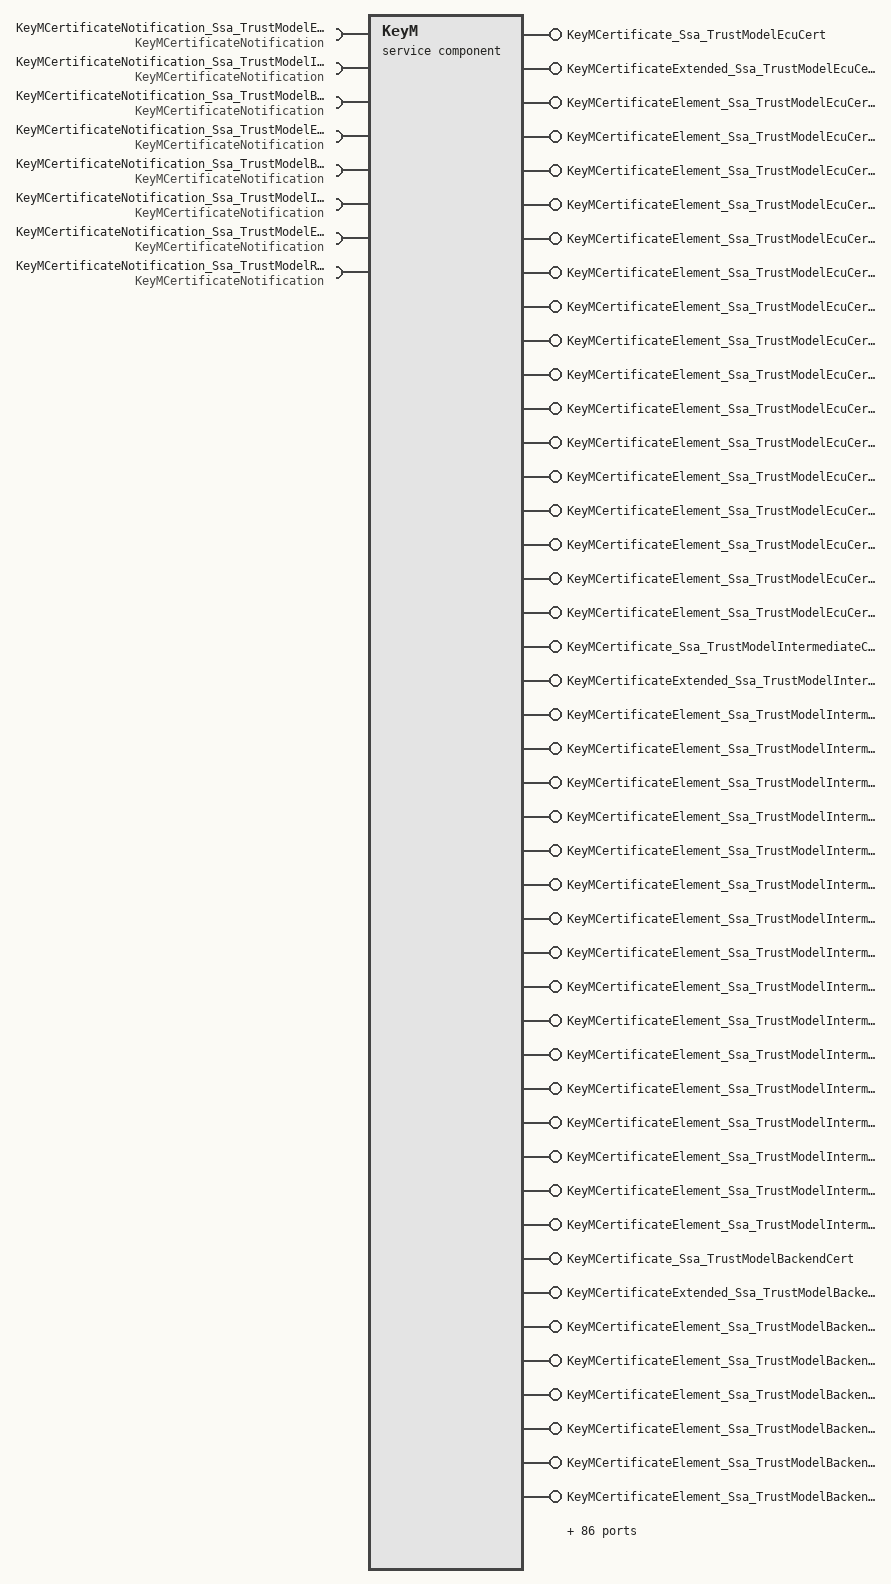
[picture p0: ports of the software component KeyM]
  service sw component type KeyM: category=SERVICE_COMPONENT
    provide port KeyMCertificate_Ssa_TrustModelEcuCert: provided-interface=KeyMCertificate_Ssa_TrustModelEcuCert  # Port to execute certificate related functions.
    provide port KeyMCertificateExtended_Ssa_TrustModelEcuCert: provided-interface=KeyMCertificateExtended_Ssa_TrustModelEcuCert  # Port to execute certificate related functions that extend the AUTOSAR scope of functionality.
    require port KeyMCertificateNotification_Ssa_TrustModelEcuCert: required-interface=KeyMCertificateNotification  # Port to execute certificate notification related functions.
    18 x provide port:
      KeyMCertificateElement_Ssa_TrustModelEcuCert_ext_authKeyId_005: provided-interface=KeyMCertificateElement_Ssa_TrustModelEcuCert_ext_authKeyId_005  # Port to execute certificate related functions.
      KeyMCertificateElement_Ssa_TrustModelEcuCert_ext_subKeyId_005: provided-interface=KeyMCertificateElement_Ssa_TrustModelEcuCert_ext_subKeyId_005  # Port to execute certificate related functions.
      KeyMCertificateElement_Ssa_TrustModelEcuCert_ext_keyUsage_005: provided-interface=KeyMCertificateElement_Ssa_TrustModelEcuCert_ext_keyUsage_005  # Port to execute certificate related functions.
      KeyMCertificateElement_Ssa_TrustModelEcuCert_Version_005: provided-interface=KeyMCertificateElement_Ssa_TrustModelEcuCert_Version_005  # Port to execute certificate related functions.
      KeyMCertificateElement_Ssa_TrustModelEcuCert_SerialNo_005: provided-interface=KeyMCertificateElement_Ssa_TrustModelEcuCert_SerialNo_005  # Port to execute certificate related functions.
      KeyMCertificateElement_Ssa_TrustModelEcuCert_SigAlgoId_005: provided-interface=KeyMCertificateElement_Ssa_TrustModelEcuCert_SigAlgoId_005  # Port to execute certificate related functions.
      KeyMCertificateElement_Ssa_TrustModelEcuCert_validityNotBefore_005: provided-interface=KeyMCertificateElement_Ssa_TrustModelEcuCert_validityNotBefore_005  # Port to execute certificate related functions.
      KeyMCertificateElement_Ssa_TrustModelEcuCert_validityNotAfter_005: provided-interface=KeyMCertificateElement_Ssa_TrustModelEcuCert_validityNotAfter_005  # Port to execute certificate related functions.
      KeyMCertificateElement_Ssa_TrustModelEcuCert_subject_005: provided-interface=KeyMCertificateElement_Ssa_TrustModelEcuCert_subject_005  # Port to execute certificate related functions.
      KeyMCertificateElement_Ssa_TrustModelEcuCert_SubjectPublicKeyInfoAlgo_005: provided-interface=KeyMCertificateElement_Ssa_TrustModelEcuCert_SubjectPublicKeyInfoAlgo_005  # Port to execute certificate related functions.
      KeyMCertificateElement_Ssa_TrustModelEcuCert_SubjectPublicKeyInfoKey_005: provided-interface=KeyMCertificateElement_Ssa_TrustModelEcuCert_SubjectPublicKeyInfoKey_005  # Port to execute certificate related functions.
      KeyMCertificateElement_Ssa_TrustModelEcuCert_Issuer_005: provided-interface=KeyMCertificateElement_Ssa_TrustModelEcuCert_Issuer_005  # Port to execute certificate related functions.
      KeyMCertificateElement_Ssa_TrustModelEcuCert_signatureAlgorithm_005: provided-interface=KeyMCertificateElement_Ssa_TrustModelEcuCert_signatureAlgorithm_005  # Port to execute certificate related functions.
      KeyMCertificateElement_Ssa_TrustModelEcuCert_signatureValue_005: provided-interface=KeyMCertificateElement_Ssa_TrustModelEcuCert_signatureValue_005  # Port to execute certificate related functions.
      KeyMCertificateElement_Ssa_TrustModelEcuCert_ext_uniqueECUID_005: provided-interface=KeyMCertificateElement_Ssa_TrustModelEcuCert_ext_uniqueECUID_005  # Port to execute certificate related functions.
      KeyMCertificateElement_Ssa_TrustModelEcuCert_ext_specialEcu_005: provided-interface=KeyMCertificateElement_Ssa_TrustModelEcuCert_ext_specialEcu_005  # Port to execute certificate related functions.
      KeyMCertificate_Ssa_TrustModelIntermediateCert: provided-interface=KeyMCertificate_Ssa_TrustModelIntermediateCert  # Port to execute certificate related functions.
      KeyMCertificateExtended_Ssa_TrustModelIntermediateCert: provided-interface=KeyMCertificateExtended_Ssa_TrustModelIntermediateCert  # Port to execute certificate related functions that extend the AUTOSAR scope of functionality.
    require port KeyMCertificateNotification_Ssa_TrustModelIntermediateCert: required-interface=KeyMCertificateNotification  # Port to execute certificate notification related functions.
    18 x provide port:
      KeyMCertificateElement_Ssa_TrustModelIntermediateCert_ext_authKeyId_003: provided-interface=KeyMCertificateElement_Ssa_TrustModelIntermediateCert_ext_authKeyId_003  # Port to execute certificate related functions.
      KeyMCertificateElement_Ssa_TrustModelIntermediateCert_ext_subKeyId_003: provided-interface=KeyMCertificateElement_Ssa_TrustModelIntermediateCert_ext_subKeyId_003  # Port to execute certificate related functions.
      KeyMCertificateElement_Ssa_TrustModelIntermediateCert_ext_basicConstraints_003: provided-interface=KeyMCertificateElement_Ssa_TrustModelIntermediateCert_ext_basicConstraints_003  # Port to execute certificate related functions.
      KeyMCertificateElement_Ssa_TrustModelIntermediateCert_ext_keyUsage_003: provided-interface=KeyMCertificateElement_Ssa_TrustModelIntermediateCert_ext_keyUsage_003  # Port to execute certificate related functions.
      KeyMCertificateElement_Ssa_TrustModelIntermediateCert_ext_pkiRole_003: provided-interface=KeyMCertificateElement_Ssa_TrustModelIntermediateCert_ext_pkiRole_003  # Port to execute certificate related functions.
      KeyMCertificateElement_Ssa_TrustModelIntermediateCert_Version_003: provided-interface=KeyMCertificateElement_Ssa_TrustModelIntermediateCert_Version_003  # Port to execute certificate related functions.
      KeyMCertificateElement_Ssa_TrustModelIntermediateCert_SerialNo_003: provided-interface=KeyMCertificateElement_Ssa_TrustModelIntermediateCert_SerialNo_003  # Port to execute certificate related functions.
      KeyMCertificateElement_Ssa_TrustModelIntermediateCert_SigAlgoId_003: provided-interface=KeyMCertificateElement_Ssa_TrustModelIntermediateCert_SigAlgoId_003  # Port to execute certificate related functions.
      KeyMCertificateElement_Ssa_TrustModelIntermediateCert_validityNotBefore_003: provided-interface=KeyMCertificateElement_Ssa_TrustModelIntermediateCert_validityNotBefore_003  # Port to execute certificate related functions.
      KeyMCertificateElement_Ssa_TrustModelIntermediateCert_validityNotAfter_003: provided-interface=KeyMCertificateElement_Ssa_TrustModelIntermediateCert_validityNotAfter_003  # Port to execute certificate related functions.
      KeyMCertificateElement_Ssa_TrustModelIntermediateCert_subject_003: provided-interface=KeyMCertificateElement_Ssa_TrustModelIntermediateCert_subject_003  # Port to execute certificate related functions.
      KeyMCertificateElement_Ssa_TrustModelIntermediateCert_SubjectPublicKeyInfoAlgo_003: provided-interface=KeyMCertificateElement_Ssa_TrustModelIntermediateCert_SubjectPublicKeyInfoAlgo_003  # Port to execute certificate related functions.
      KeyMCertificateElement_Ssa_TrustModelIntermediateCert_SubjectPublicKeyInfoKey_003: provided-interface=KeyMCertificateElement_Ssa_TrustModelIntermediateCert_SubjectPublicKeyInfoKey_003  # Port to execute certificate related functions.
      KeyMCertificateElement_Ssa_TrustModelIntermediateCert_Issuer_003: provided-interface=KeyMCertificateElement_Ssa_TrustModelIntermediateCert_Issuer_003  # Port to execute certificate related functions.
      KeyMCertificateElement_Ssa_TrustModelIntermediateCert_signatureAlgorithm_003: provided-interface=KeyMCertificateElement_Ssa_TrustModelIntermediateCert_signatureAlgorithm_003  # Port to execute certificate related functions.
      KeyMCertificateElement_Ssa_TrustModelIntermediateCert_signatureValue_003: provided-interface=KeyMCertificateElement_Ssa_TrustModelIntermediateCert_signatureValue_003  # Port to execute certificate related functions.
      KeyMCertificate_Ssa_TrustModelBackendCert: provided-interface=KeyMCertificate_Ssa_TrustModelBackendCert  # Port to execute certificate related functions.
      KeyMCertificateExtended_Ssa_TrustModelBackendCert: provided-interface=KeyMCertificateExtended_Ssa_TrustModelBackendCert  # Port to execute certificate related functions that extend the AUTOSAR scope of functionality.
    require port KeyMCertificateNotification_Ssa_TrustModelBackendCert: required-interface=KeyMCertificateNotification  # Port to execute certificate notification related functions.
    18 x provide port:
      KeyMCertificateElement_Ssa_TrustModelBackendCert_ext_authKeyId_002: provided-interface=KeyMCertificateElement_Ssa_TrustModelBackendCert_ext_authKeyId_002  # Port to execute certificate related functions.
      KeyMCertificateElement_Ssa_TrustModelBackendCert_ext_subKeyId_002: provided-interface=KeyMCertificateElement_Ssa_TrustModelBackendCert_ext_subKeyId_002  # Port to execute certificate related functions.
      KeyMCertificateElement_Ssa_TrustModelBackendCert_ext_basicConstraints_002: provided-interface=KeyMCertificateElement_Ssa_TrustModelBackendCert_ext_basicConstraints_002  # Port to execute certificate related functions.
      KeyMCertificateElement_Ssa_TrustModelBackendCert_ext_keyUsage_002: provided-interface=KeyMCertificateElement_Ssa_TrustModelBackendCert_ext_keyUsage_002  # Port to execute certificate related functions.
      KeyMCertificateElement_Ssa_TrustModelBackendCert_ext_pkiRole_002: provided-interface=KeyMCertificateElement_Ssa_TrustModelBackendCert_ext_pkiRole_002  # Port to execute certificate related functions.
      KeyMCertificateElement_Ssa_TrustModelBackendCert_Version_002: provided-interface=KeyMCertificateElement_Ssa_TrustModelBackendCert_Version_002  # Port to execute certificate related functions.
      KeyMCertificateElement_Ssa_TrustModelBackendCert_SerialNo_002: provided-interface=KeyMCertificateElement_Ssa_TrustModelBackendCert_SerialNo_002  # Port to execute certificate related functions.
      KeyMCertificateElement_Ssa_TrustModelBackendCert_SigAlgoId_002: provided-interface=KeyMCertificateElement_Ssa_TrustModelBackendCert_SigAlgoId_002  # Port to execute certificate related functions.
      KeyMCertificateElement_Ssa_TrustModelBackendCert_validityNotBefore_002: provided-interface=KeyMCertificateElement_Ssa_TrustModelBackendCert_validityNotBefore_002  # Port to execute certificate related functions.
      KeyMCertificateElement_Ssa_TrustModelBackendCert_validityNotAfter_002: provided-interface=KeyMCertificateElement_Ssa_TrustModelBackendCert_validityNotAfter_002  # Port to execute certificate related functions.
      KeyMCertificateElement_Ssa_TrustModelBackendCert_subject_002: provided-interface=KeyMCertificateElement_Ssa_TrustModelBackendCert_subject_002  # Port to execute certificate related functions.
      KeyMCertificateElement_Ssa_TrustModelBackendCert_SubjectPublicKeyInfoAlgo_002: provided-interface=KeyMCertificateElement_Ssa_TrustModelBackendCert_SubjectPublicKeyInfoAlgo_002  # Port to execute certificate related functions.
      KeyMCertificateElement_Ssa_TrustModelBackendCert_SubjectPublicKeyInfoKey_002: provided-interface=KeyMCertificateElement_Ssa_TrustModelBackendCert_SubjectPublicKeyInfoKey_002  # Port to execute certificate related functions.
      KeyMCertificateElement_Ssa_TrustModelBackendCert_Issuer_002: provided-interface=KeyMCertificateElement_Ssa_TrustModelBackendCert_Issuer_002  # Port to execute certificate related functions.
      KeyMCertificateElement_Ssa_TrustModelBackendCert_signatureAlgorithm_002: provided-interface=KeyMCertificateElement_Ssa_TrustModelBackendCert_signatureAlgorithm_002  # Port to execute certificate related functions.
      KeyMCertificateElement_Ssa_TrustModelBackendCert_signatureValue_002: provided-interface=KeyMCertificateElement_Ssa_TrustModelBackendCert_signatureValue_002  # Port to execute certificate related functions.
      KeyMCertificate_Ssa_TrustModelEcuPeerCert: provided-interface=KeyMCertificate_Ssa_TrustModelEcuPeerCert  # Port to execute certificate related functions.
      KeyMCertificateExtended_Ssa_TrustModelEcuPeerCert: provided-interface=KeyMCertificateExtended_Ssa_TrustModelEcuPeerCert  # Port to execute certificate related functions that extend the AUTOSAR scope of functionality.
    require port KeyMCertificateNotification_Ssa_TrustModelEcuPeerCert: required-interface=KeyMCertificateNotification  # Port to execute certificate notification related functions.
    18 x provide port:
      KeyMCertificateElement_Ssa_TrustModelEcuPeerCert_ext_authKeyId_006: provided-interface=KeyMCertificateElement_Ssa_TrustModelEcuPeerCert_ext_authKeyId_006  # Port to execute certificate related functions.
      KeyMCertificateElement_Ssa_TrustModelEcuPeerCert_ext_subKeyId_006: provided-interface=KeyMCertificateElement_Ssa_TrustModelEcuPeerCert_ext_subKeyId_006  # Port to execute certificate related functions.
      KeyMCertificateElement_Ssa_TrustModelEcuPeerCert_ext_keyUsage_006: provided-interface=KeyMCertificateElement_Ssa_TrustModelEcuPeerCert_ext_keyUsage_006  # Port to execute certificate related functions.
      KeyMCertificateElement_Ssa_TrustModelEcuPeerCert_Version_006: provided-interface=KeyMCertificateElement_Ssa_TrustModelEcuPeerCert_Version_006  # Port to execute certificate related functions.
      KeyMCertificateElement_Ssa_TrustModelEcuPeerCert_SerialNo_006: provided-interface=KeyMCertificateElement_Ssa_TrustModelEcuPeerCert_SerialNo_006  # Port to execute certificate related functions.
      KeyMCertificateElement_Ssa_TrustModelEcuPeerCert_SigAlgoId_006: provided-interface=KeyMCertificateElement_Ssa_TrustModelEcuPeerCert_SigAlgoId_006  # Port to execute certificate related functions.
      KeyMCertificateElement_Ssa_TrustModelEcuPeerCert_validityNotBefore_006: provided-interface=KeyMCertificateElement_Ssa_TrustModelEcuPeerCert_validityNotBefore_006  # Port to execute certificate related functions.
      KeyMCertificateElement_Ssa_TrustModelEcuPeerCert_validityNotAfter_006: provided-interface=KeyMCertificateElement_Ssa_TrustModelEcuPeerCert_validityNotAfter_006  # Port to execute certificate related functions.
      KeyMCertificateElement_Ssa_TrustModelEcuPeerCert_subject_006: provided-interface=KeyMCertificateElement_Ssa_TrustModelEcuPeerCert_subject_006  # Port to execute certificate related functions.
      KeyMCertificateElement_Ssa_TrustModelEcuPeerCert_SubjectPublicKeyInfoAlgo_006: provided-interface=KeyMCertificateElement_Ssa_TrustModelEcuPeerCert_SubjectPublicKeyInfoAlgo_006  # Port to execute certificate related functions.
      KeyMCertificateElement_Ssa_TrustModelEcuPeerCert_SubjectPublicKeyInfoKey_006: provided-interface=KeyMCertificateElement_Ssa_TrustModelEcuPeerCert_SubjectPublicKeyInfoKey_006  # Port to execute certificate related functions.
      KeyMCertificateElement_Ssa_TrustModelEcuPeerCert_Issuer_006: provided-interface=KeyMCertificateElement_Ssa_TrustModelEcuPeerCert_Issuer_006  # Port to execute certificate related functions.
      KeyMCertificateElement_Ssa_TrustModelEcuPeerCert_signatureAlgorithm_006: provided-interface=KeyMCertificateElement_Ssa_TrustModelEcuPeerCert_signatureAlgorithm_006  # Port to execute certificate related functions.
      KeyMCertificateElement_Ssa_TrustModelEcuPeerCert_signatureValue_006: provided-interface=KeyMCertificateElement_Ssa_TrustModelEcuPeerCert_signatureValue_006  # Port to execute certificate related functions.
      KeyMCertificateElement_Ssa_TrustModelEcuPeerCert_ext_uniqueECUID_006: provided-interface=KeyMCertificateElement_Ssa_TrustModelEcuPeerCert_ext_uniqueECUID_006  # Port to execute certificate related functions.
      KeyMCertificateElement_Ssa_TrustModelEcuPeerCert_ext_specialEcu_006: provided-interface=KeyMCertificateElement_Ssa_TrustModelEcuPeerCert_ext_specialEcu_006  # Port to execute certificate related functions.
      KeyMCertificate_Ssa_TrustModelBackendPeerCert: provided-interface=KeyMCertificate_Ssa_TrustModelBackendPeerCert  # Port to execute certificate related functions.
      KeyMCertificateExtended_Ssa_TrustModelBackendPeerCert: provided-interface=KeyMCertificateExtended_Ssa_TrustModelBackendPeerCert  # Port to execute certificate related functions that extend the AUTOSAR scope of functionality.
    require port KeyMCertificateNotification_Ssa_TrustModelBackendPeerCert: required-interface=KeyMCertificateNotification  # Port to execute certificate notification related functions.
    18 x provide port:
      KeyMCertificateElement_Ssa_TrustModelBackendPeerCert_ext_authKeyId_004: provided-interface=KeyMCertificateElement_Ssa_TrustModelBackendPeerCert_ext_authKeyId_004  # Port to execute certificate related functions.
      KeyMCertificateElement_Ssa_TrustModelBackendPeerCert_ext_subKeyId_004: provided-interface=KeyMCertificateElement_Ssa_TrustModelBackendPeerCert_ext_subKeyId_004  # Port to execute certificate related functions.
      KeyMCertificateElement_Ssa_TrustModelBackendPeerCert_ext_basicConstraints_004: provided-interface=KeyMCertificateElement_Ssa_TrustModelBackendPeerCert_ext_basicConstraints_004  # Port to execute certificate related functions.
      KeyMCertificateElement_Ssa_TrustModelBackendPeerCert_ext_keyUsage_004: provided-interface=KeyMCertificateElement_Ssa_TrustModelBackendPeerCert_ext_keyUsage_004  # Port to execute certificate related functions.
      KeyMCertificateElement_Ssa_TrustModelBackendPeerCert_ext_pkiRole_004: provided-interface=KeyMCertificateElement_Ssa_TrustModelBackendPeerCert_ext_pkiRole_004  # Port to execute certificate related functions.
      KeyMCertificateElement_Ssa_TrustModelBackendPeerCert_Version_004: provided-interface=KeyMCertificateElement_Ssa_TrustModelBackendPeerCert_Version_004  # Port to execute certificate related functions.
      KeyMCertificateElement_Ssa_TrustModelBackendPeerCert_SerialNo_004: provided-interface=KeyMCertificateElement_Ssa_TrustModelBackendPeerCert_SerialNo_004  # Port to execute certificate related functions.
      KeyMCertificateElement_Ssa_TrustModelBackendPeerCert_SigAlgoId_004: provided-interface=KeyMCertificateElement_Ssa_TrustModelBackendPeerCert_SigAlgoId_004  # Port to execute certificate related functions.
      KeyMCertificateElement_Ssa_TrustModelBackendPeerCert_validityNotBefore_004: provided-interface=KeyMCertificateElement_Ssa_TrustModelBackendPeerCert_validityNotBefore_004  # Port to execute certificate related functions.
      KeyMCertificateElement_Ssa_TrustModelBackendPeerCert_validityNotAfter_004: provided-interface=KeyMCertificateElement_Ssa_TrustModelBackendPeerCert_validityNotAfter_004  # Port to execute certificate related functions.
      KeyMCertificateElement_Ssa_TrustModelBackendPeerCert_subject_004: provided-interface=KeyMCertificateElement_Ssa_TrustModelBackendPeerCert_subject_004  # Port to execute certificate related functions.
      KeyMCertificateElement_Ssa_TrustModelBackendPeerCert_SubjectPublicKeyInfoAlgo_004: provided-interface=KeyMCertificateElement_Ssa_TrustModelBackendPeerCert_SubjectPublicKeyInfoAlgo_004  # Port to execute certificate related functions.
      KeyMCertificateElement_Ssa_TrustModelBackendPeerCert_SubjectPublicKeyInfoKey_004: provided-interface=KeyMCertificateElement_Ssa_TrustModelBackendPeerCert_SubjectPublicKeyInfoKey_004  # Port to execute certificate related functions.
      KeyMCertificateElement_Ssa_TrustModelBackendPeerCert_Issuer_004: provided-interface=KeyMCertificateElement_Ssa_TrustModelBackendPeerCert_Issuer_004  # Port to execute certificate related functions.
      KeyMCertificateElement_Ssa_TrustModelBackendPeerCert_signatureAlgorithm_004: provided-interface=KeyMCertificateElement_Ssa_TrustModelBackendPeerCert_signatureAlgorithm_004  # Port to execute certificate related functions.
      KeyMCertificateElement_Ssa_TrustModelBackendPeerCert_signatureValue_004: provided-interface=KeyMCertificateElement_Ssa_TrustModelBackendPeerCert_signatureValue_004  # Port to execute certificate related functions.
      KeyMCertificate_Ssa_TrustModelIntermediatePeerCert: provided-interface=KeyMCertificate_Ssa_TrustModelIntermediatePeerCert  # Port to execute certificate related functions.
      KeyMCertificateExtended_Ssa_TrustModelIntermediatePeerCert: provided-interface=KeyMCertificateExtended_Ssa_TrustModelIntermediatePeerCert  # Port to execute certificate related functions that extend the AUTOSAR scope of functionality.
    require port KeyMCertificateNotification_Ssa_TrustModelIntermediatePeerCert: required-interface=KeyMCertificateNotification  # Port to execute certificate notification related functions.
    17 x provide port:
      KeyMCertificateElement_Ssa_TrustModelIntermediatePeerCert_ext_authKeyId_007: provided-interface=KeyMCertificateElement_Ssa_TrustModelIntermediatePeerCert_ext_authKeyId_007  # Port to execute certificate related functions.
      KeyMCertificateElement_Ssa_TrustModelIntermediatePeerCert_ext_subKeyId_007: provided-interface=KeyMCertificateElement_Ssa_TrustModelIntermediatePeerCert_ext_subKeyId_007  # Port to execute certificate related functions.
      KeyMCertificateElement_Ssa_TrustModelIntermediatePeerCert_ext_basicConstraints_005: provided-interface=KeyMCertificateElement_Ssa_TrustModelIntermediatePeerCert_ext_basicConstraints_005  # Port to execute certificate related functions.
      KeyMCertificateElement_Ssa_TrustModelIntermediatePeerCert_ext_keyUsage_007: provided-interface=KeyMCertificateElement_Ssa_TrustModelIntermediatePeerCert_ext_keyUsage_007  # Port to execute certificate related functions.
      KeyMCertificateElement_Ssa_TrustModelIntermediatePeerCert_Version_007: provided-interface=KeyMCertificateElement_Ssa_TrustModelIntermediatePeerCert_Version_007  # Port to execute certificate related functions.
      KeyMCertificateElement_Ssa_TrustModelIntermediatePeerCert_SerialNo_007: provided-interface=KeyMCertificateElement_Ssa_TrustModelIntermediatePeerCert_SerialNo_007  # Port to execute certificate related functions.
      KeyMCertificateElement_Ssa_TrustModelIntermediatePeerCert_SigAlgoId_007: provided-interface=KeyMCertificateElement_Ssa_TrustModelIntermediatePeerCert_SigAlgoId_007  # Port to execute certificate related functions.
      KeyMCertificateElement_Ssa_TrustModelIntermediatePeerCert_validityNotBefore_007: provided-interface=KeyMCertificateElement_Ssa_TrustModelIntermediatePeerCert_validityNotBefore_007  # Port to execute certificate related functions.
      KeyMCertificateElement_Ssa_TrustModelIntermediatePeerCert_validityNotAfter_007: provided-interface=KeyMCertificateElement_Ssa_TrustModelIntermediatePeerCert_validityNotAfter_007  # Port to execute certificate related functions.
      KeyMCertificateElement_Ssa_TrustModelIntermediatePeerCert_subject_007: provided-interface=KeyMCertificateElement_Ssa_TrustModelIntermediatePeerCert_subject_007  # Port to execute certificate related functions.
      KeyMCertificateElement_Ssa_TrustModelIntermediatePeerCert_SubjectPublicKeyInfoAlgo_007: provided-interface=KeyMCertificateElement_Ssa_TrustModelIntermediatePeerCert_SubjectPublicKeyInfoAlgo_007  # Port to execute certificate related functions.
      KeyMCertificateElement_Ssa_TrustModelIntermediatePeerCert_SubjectPublicKeyInfoKey_007: provided-interface=KeyMCertificateElement_Ssa_TrustModelIntermediatePeerCert_SubjectPublicKeyInfoKey_007  # Port to execute certificate related functions.
      KeyMCertificateElement_Ssa_TrustModelIntermediatePeerCert_Issuer_007: provided-interface=KeyMCertificateElement_Ssa_TrustModelIntermediatePeerCert_Issuer_007  # Port to execute certificate related functions.
      KeyMCertificateElement_Ssa_TrustModelIntermediatePeerCert_signatureAlgorithm_007: provided-interface=KeyMCertificateElement_Ssa_TrustModelIntermediatePeerCert_signatureAlgorithm_007  # Port to execute certificate related functions.
      KeyMCertificateElement_Ssa_TrustModelIntermediatePeerCert_signatureValue_007: provided-interface=KeyMCertificateElement_Ssa_TrustModelIntermediatePeerCert_signatureValue_007  # Port to execute certificate related functions.
      KeyMCertificate_Ssa_TrustModelEcuCsr: provided-interface=KeyMCertificate_Ssa_TrustModelEcuCsr  # Port to execute certificate related functions.
      KeyMCertificateExtended_Ssa_TrustModelEcuCsr: provided-interface=KeyMCertificateExtended_Ssa_TrustModelEcuCsr  # Port to execute certificate related functions that extend the AUTOSAR scope of functionality.
    require port KeyMCertificateNotification_Ssa_TrustModelEcuCsr: required-interface=KeyMCertificateNotification  # Port to execute certificate notification related functions.
    23 x provide port:
      KeyMCertificateElement_Ssa_TrustModelEcuCsr_ext_authKeyId_008: provided-interface=KeyMCertificateElement_Ssa_TrustModelEcuCsr_ext_authKeyId_008  # Port to execute certificate related functions.
      KeyMCertificateElement_Ssa_TrustModelEcuCsr_ext_subKeyId_008: provided-interface=KeyMCertificateElement_Ssa_TrustModelEcuCsr_ext_subKeyId_008  # Port to execute certificate related functions.
      KeyMCertificateElement_Ssa_TrustModelEcuCsr_ext_keyUsage_008: provided-interface=KeyMCertificateElement_Ssa_TrustModelEcuCsr_ext_keyUsage_008  # Port to execute certificate related functions.
      KeyMCertificateElement_Ssa_TrustModelEcuCsr_ext_pkiRole_008: provided-interface=KeyMCertificateElement_Ssa_TrustModelEcuCsr_ext_pkiRole_008  # Port to execute certificate related functions.
      KeyMCertificateElement_Ssa_TrustModelEcuCsr_Version_008: provided-interface=KeyMCertificateElement_Ssa_TrustModelEcuCsr_Version_008  # Port to execute certificate related functions.
      KeyMCertificateElement_Ssa_TrustModelEcuCsr_SerialNo_008: provided-interface=KeyMCertificateElement_Ssa_TrustModelEcuCsr_SerialNo_008  # Port to execute certificate related functions.
      KeyMCertificateElement_Ssa_TrustModelEcuCsr_SigAlgoId_008: provided-interface=KeyMCertificateElement_Ssa_TrustModelEcuCsr_SigAlgoId_008  # Port to execute certificate related functions.
      KeyMCertificateElement_Ssa_TrustModelEcuCsr_validityNotBefore_008: provided-interface=KeyMCertificateElement_Ssa_TrustModelEcuCsr_validityNotBefore_008  # Port to execute certificate related functions.
      KeyMCertificateElement_Ssa_TrustModelEcuCsr_validityNotAfter_008: provided-interface=KeyMCertificateElement_Ssa_TrustModelEcuCsr_validityNotAfter_008  # Port to execute certificate related functions.
      KeyMCertificateElement_Ssa_TrustModelEcuCsr_subject_008: provided-interface=KeyMCertificateElement_Ssa_TrustModelEcuCsr_subject_008  # Port to execute certificate related functions.
      KeyMCertificateElement_Ssa_TrustModelEcuCsr_SubjectPublicKeyInfoAlgo_008: provided-interface=KeyMCertificateElement_Ssa_TrustModelEcuCsr_SubjectPublicKeyInfoAlgo_008  # Port to execute certificate related functions.
      KeyMCertificateElement_Ssa_TrustModelEcuCsr_SubjectPublicKeyInfoKey_008: provided-interface=KeyMCertificateElement_Ssa_TrustModelEcuCsr_SubjectPublicKeyInfoKey_008  # Port to execute certificate related functions.
      KeyMCertificateElement_Ssa_TrustModelEcuCsr_Issuer_008: provided-interface=KeyMCertificateElement_Ssa_TrustModelEcuCsr_Issuer_008  # Port to execute certificate related functions.
      KeyMCertificateElement_Ssa_TrustModelEcuCsr_signatureAlgorithm_008: provided-interface=KeyMCertificateElement_Ssa_TrustModelEcuCsr_signatureAlgorithm_008  # Port to execute certificate related functions.
      KeyMCertificateElement_Ssa_TrustModelEcuCsr_signatureValue_008: provided-interface=KeyMCertificateElement_Ssa_TrustModelEcuCsr_signatureValue_008  # Port to execute certificate related functions.
      KeyMCertificateElement_Ssa_TrustModelEcuCsr_ext_uniqueECUID_007: provided-interface=KeyMCertificateElement_Ssa_TrustModelEcuCsr_ext_uniqueECUID_007  # Port to execute certificate related functions.
      KeyMCertificateElement_Ssa_TrustModelEcuCsr_ext_specialEcu_007: provided-interface=KeyMCertificateElement_Ssa_TrustModelEcuCsr_ext_specialEcu_007  # Port to execute certificate related functions.
      KeyMCertificateElement_Ssa_TrustModelEcuCsr_ext_extKeyUsage_007: provided-interface=KeyMCertificateElement_Ssa_TrustModelEcuCsr_ext_extKeyUsage_007  # Port to execute certificate related functions.
      KeyMCertificateElement_Ssa_TrustModelEcuCsr_ext_extKeyUsage_oid{1..3}_007: provided-interface=KeyMCertificateElement_Ssa_TrustModelEcuCsr_ext_extKeyUsage_oid{1..3}_007  # Port to execute certificate related functions.
      KeyMCertificate_Ssa_TrustModelRootCert: provided-interface=KeyMCertificate_Ssa_TrustModelRootCert  # Port to execute certificate related functions.
      KeyMCertificateExtended_Ssa_TrustModelRootCert: provided-interface=KeyMCertificateExtended_Ssa_TrustModelRootCert  # Port to execute certificate related functions that extend the AUTOSAR scope of functionality.
    require port KeyMCertificateNotification_Ssa_TrustModelRootCert: required-interface=KeyMCertificateNotification  # Port to execute certificate notification related functions.
